VERSION "dbc-export 1 2025.20.8"

NS_ :

BS_:

BU_: BMS CP DAS DIF GTW HVP ICR PCS SCCM VCFRONT VCLEFT VCRIGHT VCSEC

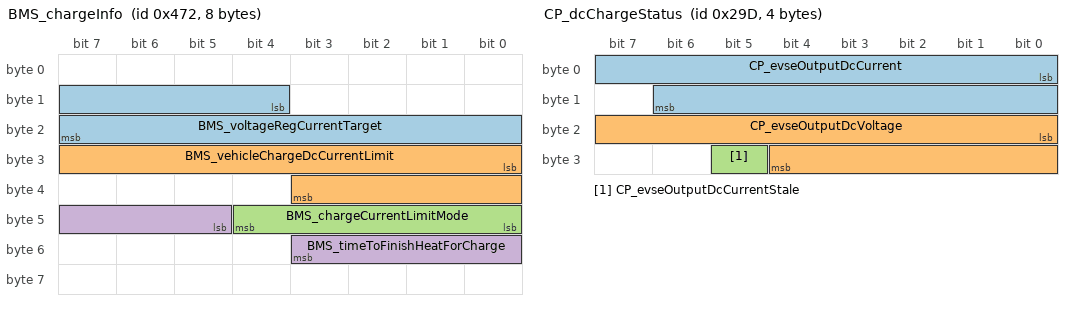
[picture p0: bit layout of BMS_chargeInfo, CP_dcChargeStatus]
BO_ 1138 BMS_chargeInfo: 8 BMS
 SG_ BMS_voltageRegCurrentTarget : 12|12@1+ (0.5,0) [0|2047.5] "A" Vector__XXX
 SG_ BMS_vehicleChargeDcCurrentLimit : 24|12@1+ (0.5,0) [0|2047.5] "A" Vector__XXX
 SG_ BMS_chargeCurrentLimitMode : 40|5@1+ (1,0) [0|31] "" Vector__XXX
 SG_ BMS_timeToFinishHeatForCharge : 45|7@1+ (5,0) [0|600] "min" Vector__XXX

BO_ 658 BMS_socStatus: 8 BMS
 SG_ BMS_userChargeCurrentLimitMode : 58|3@1+ (1,0) [0|7] "" Vector__XXX

BO_ 669 CP_dcChargeStatus: 4 CP
 SG_ CP_evseOutputDcCurrent : 0|15@1- (0.125,0) [-2048|2047.875] "A" Vector__XXX
 SG_ CP_evseOutputDcVoltage : 16|13@1+ (0.07324219,0) [0|599.92675822] "V" Vector__XXX
 SG_ CP_evseOutputDcCurrentStale : 29|1@1+ (1,0) [0|1] "" Vector__XXX

BO_ 541 CP_evseStatus: 8 CP
 SG_ CP_evseAccept : 0|1@1+ (1,0) [0|1] "" Vector__XXX
 SG_ CP_evseRequest : 1|1@1+ (1,0) [0|1] "" Vector__XXX
 SG_ CP_proximity : 2|2@1+ (1,0) [1|3] "" Vector__XXX
 SG_ CP_pilot : 4|3@1+ (1,0) [0|6] "" Vector__XXX
 SG_ CP_digitalCommsEstablished : 7|1@1+ (1,0) [0|1] "" Vector__XXX
 SG_ CP_pilotCurrent : 8|8@1+ (0.5,0) [0|127.5] "A" Vector__XXX
 SG_ CP_cableType : 16|3@1+ (1,0) [0|7] "" Vector__XXX
 SG_ CP_iecPilotState : 19|4@1+ (1,0) [0|15] "" Vector__XXX
 SG_ CP_plcSupported : 23|1@1+ (1,0) [0|1] "" Vector__XXX
 SG_ CP_cableCurrentLimit : 24|7@1+ (1,0) [0|127] "A" Vector__XXX
 SG_ CP_teslaSwcanState : 34|4@1+ (1,0) [0|15] "" Vector__XXX
 SG_ CP_evseChargeType_UI : 38|2@1+ (1,0) [0|3] "" Vector__XXX
 SG_ CP_gbState : 40|4@1+ (1,0) [0|15] "" Vector__XXX
 SG_ CP_gbdcStopChargeReason : 44|4@1+ (1,0) [0|15] "" Vector__XXX
 SG_ CP_gbdcFailureReason : 48|2@1+ (1,0) [0|3] "" Vector__XXX
 SG_ CP_gbdcChargeAttempts : 50|2@1+ (1,0) [0|3] "" Vector__XXX
 SG_ CP_acChargeState : 52|3@1+ (1,0) [0|7] "" Vector__XXX
 SG_ CP_teslaDcState : 56|4@1+ (1,0) [0|15] "" Vector__XXX

BO_ 1001 DAS_bodyControls: 8 DAS
 SG_ DAS_headlightRequest : 0|2@1+ (1,0) [0|3] "" Vector__XXX
 SG_ DAS_hazardLightRequest : 2|2@1+ (1,0) [0|2] "" Vector__XXX
 SG_ DAS_wiperSpeed : 4|4@1+ (1,0) [0|15] "" Vector__XXX
 SG_ DAS_turnIndicatorRequest : 8|3@1+ (1,0) [0|7] "" Vector__XXX
 SG_ DAS_highLowBeamDecision : 11|2@1+ (1,0) [0|2] "" Vector__XXX
 SG_ DAS_heaterRequest : 13|2@1+ (1,0) [1|3] "" Vector__XXX
 SG_ DAS_highLowBeamOffReason : 15|3@1+ (1,0) [0|7] "" Vector__XXX
 SG_ DAS_forwardCamHeaterDutyCycle : 18|4@1+ (0.06666667,0) [0|1] "-" Vector__XXX
 SG_ DAS_dynamicBrakeLightRequest : 22|1@1+ (1,0) [0|1] "" Vector__XXX
 SG_ DAS_radarHeaterRequest : 23|1@1+ (1,0) [0|1] "" Vector__XXX
 SG_ DAS_ahlbOverride : 24|1@1+ (1,0) [0|1] "" Vector__XXX
 SG_ DAS_mirrorFoldRequest : 25|2@1+ (1,0) [0|2] "" Vector__XXX
 SG_ DAS_wiperWashRequest : 27|1@1+ (1,0) [0|1] "" Vector__XXX
 SG_ DAS_ulcConfirmationRequestActive : 28|1@1+ (1,0) [0|1] "" Vector__XXX
 SG_ DAS_overrideWiperSetting : 29|1@1+ (1,0) [0|1] "" Vector__XXX
 SG_ DAS_autoWiperState : 30|3@1+ (1,0) [0|7] "" Vector__XXX
 SG_ DAS_turnIndicatorRequestReason : 33|5@1+ (1,0) [0|31] "" Vector__XXX
 SG_ DAS_forwardRadarPowerRequest : 38|1@1+ (1,0) [0|1] "" Vector__XXX
 SG_ DAS_driverDomeLightRequest : 39|1@1+ (1,0) [0|1] "" Vector__XXX
 SG_ DAS_drivePowerStateRequest : 43|1@1+ (1,0) [0|1] "" Vector__XXX
 SG_ DAS_enableIcrDataCollection : 44|1@1+ (1,0) [0|1] "" Vector__XXX
 SG_ DAS_rPillarCamHeaterDutyCycle : 45|4@1+ (0.06666667,0) [0|1] "-" Vector__XXX
 SG_ DAS_adaptiveHighBeamIsFaulted : 49|1@1+ (1,0) [0|1] "" Vector__XXX
 SG_ DAS_restrictDoorReleaseLeft : 50|1@1+ (1,0) [0|1] "" Vector__XXX
 SG_ DAS_restrictDoorReleaseRight : 51|1@1+ (1,0) [0|1] "" Vector__XXX
 SG_ DAS_bodyControlsCounter : 52|4@1+ (1,0) [0|15] "" Vector__XXX
 SG_ DAS_bodyControlsChecksum : 56|8@1+ (1,0) [0|255] "" Vector__XXX

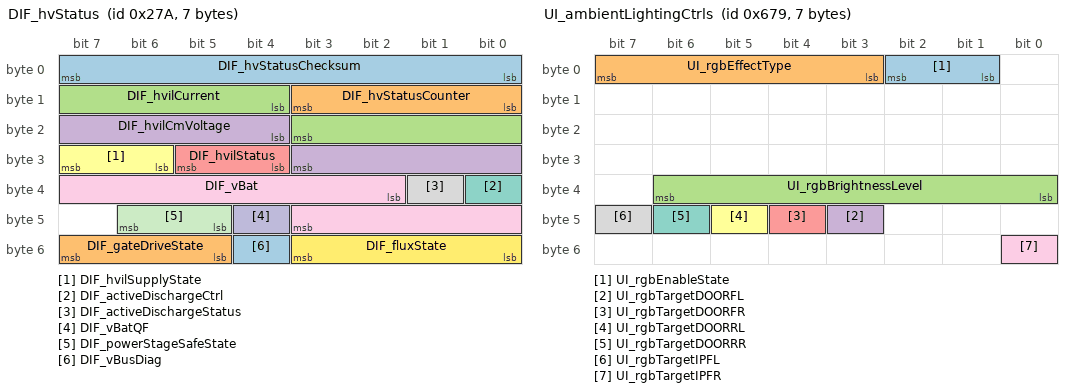
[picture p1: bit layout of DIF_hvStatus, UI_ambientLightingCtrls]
BO_ 634 DIF_hvStatus: 7 DIF
 SG_ DIF_hvStatusChecksum : 0|8@1+ (1,0) [0|255] "" Vector__XXX
 SG_ DIF_hvStatusCounter : 8|4@1+ (1,0) [0|15] "" Vector__XXX
 SG_ DIF_hvilCurrent : 12|8@1+ (0.1,0) [0|25.5] "mA" Vector__XXX
 SG_ DIF_hvilCmVoltage : 20|8@1+ (0.08,0) [0|20.4] "V" Vector__XXX
 SG_ DIF_hvilStatus : 28|2@1+ (1,0) [0|2] "" Vector__XXX
 SG_ DIF_hvilSupplyState : 30|2@1+ (1,0) [0|3] "" Vector__XXX
 SG_ DIF_activeDischargeCtrl : 32|1@1+ (1,0) [0|1] "" Vector__XXX
 SG_ DIF_activeDischargeStatus : 33|1@1+ (1,0) [0|1] "" Vector__XXX
 SG_ DIF_vBat : 34|10@1+ (1,0) [0|1023] "V" Vector__XXX
 SG_ DIF_vBatQF : 44|1@1+ (1,0) [0|1] "" Vector__XXX
 SG_ DIF_powerStageSafeState : 45|2@1+ (1,0) [0|3] "" Vector__XXX
 SG_ DIF_fluxState : 48|4@1+ (1,0) [0|15] "" Vector__XXX
 SG_ DIF_vBusDiag : 52|1@1+ (1,0) [0|1] "" Vector__XXX
 SG_ DIF_gateDriveState : 53|3@1+ (1,0) [0|7] "" Vector__XXX

BO_ 784 HVP_info: 8 HVP
 SG_ HVP_infoIndex M : 0|8@1+ (1,0) [0|255] "" Vector__XXX
 SG_ HVP_buildType m10 : 8|3@1+ (1,0) [0|7] "" Vector__XXX
 SG_ HVP_buildConfigId m10 : 16|16@1+ (1,0) [0|65535] "" Vector__XXX
 SG_ HVP_hardwareId m10 : 32|16@1+ (1,0) [0|65535] "" Vector__XXX
 SG_ HVP_componentId m10 : 48|16@1+ (1,0) [0|65535] "" Vector__XXX
 SG_ HVP_pcbaId m11 : 16|8@1+ (1,0) [0|255] "" Vector__XXX
 SG_ HVP_assemblyId m11 : 24|8@1+ (1,0) [0|255] "" Vector__XXX
 SG_ HVP_usageId m11 : 32|16@1+ (1,0) [0|65535] "" Vector__XXX
 SG_ HVP_subUsageId m11 : 48|16@1+ (1,0) [0|65535] "" Vector__XXX
 SG_ HVP_platformType m13 : 8|8@1+ (1,0) [0|255] "" Vector__XXX
 SG_ HVP_appCrc m13 : 32|32@1+ (1,0) [0|4294967295] "" Vector__XXX
 SG_ HVP_appGitHash m17 : 8|56@1+ (1,0) [0|7.20575940379e+16] "" Vector__XXX
 SG_ HVP_bootGitHash m18 : 8|56@1+ (1,0) [0|7.20575940379e+16] "" Vector__XXX
 SG_ HVP_bootUdsProtoVersion m20 : 8|8@1+ (1,0) [0|255] "" Vector__XXX
 SG_ HVP_bootCrc m20 : 32|32@1+ (1,0) [0|4294967295] "" Vector__XXX

BO_ 941 ICR_info: 8 ICR
 SG_ ICR_infoIndex M : 0|8@1+ (1,0) [0|255] "" Vector__XXX
 SG_ ICR_infoBuildType m10 : 8|3@1+ (1,0) [0|7] "" Vector__XXX
 SG_ ICR_infoPcbaId m11 : 32|8@1+ (1,0) [0|255] "" Vector__XXX
 SG_ ICR_infoAssemblyId m11 : 40|8@1+ (1,0) [0|255] "" Vector__XXX
 SG_ ICR_infoUsageId m11 : 48|16@1+ (1,0) [0|65535] "" Vector__XXX
 SG_ ICR_infoAppCrc m13 : 8|32@1+ (1,0) [0|4294967295] "" Vector__XXX
 SG_ ICR_infoBoardPartNumber17 m25 : 8|56@1+ (1,0) [0|7.20575940379e+16] "" Vector__XXX
 SG_ ICR_infoBoardPartNumber814 m26 : 8|56@1+ (1,0) [0|7.20575940379e+16] "" Vector__XXX
 SG_ ICR_infoBoardPartNumber1520 m27 : 8|48@1+ (1,0) [0|281474976710655] "" Vector__XXX

BO_ 964 PCS_info: 8 PCS
 SG_ PCS_infoIndex M : 0|8@1+ (1,0) [0|255] "" Vector__XXX
 SG_ PCS_buildType m10 : 8|8@1+ (1,0) [0|255] "" Vector__XXX
 SG_ PCS_buildConfigId m10 : 16|16@1+ (1,0) [0|65535] "" Vector__XXX
 SG_ PCS_hardwareId m10 : 32|16@1+ (1,0) [0|65535] "" Vector__XXX
 SG_ PCS_componentId m10 : 48|16@1+ (1,0) [0|65535] "" Vector__XXX
 SG_ PCS_pcbaId m11 : 16|8@1+ (1,0) [0|255] "" Vector__XXX
 SG_ PCS_assemblyId m11 : 24|8@1+ (1,0) [0|255] "" Vector__XXX
 SG_ PCS_usageId m11 : 32|16@1+ (1,0) [0|65535] "" Vector__XXX
 SG_ PCS_subUsageId m11 : 48|16@1+ (1,0) [0|65535] "" Vector__XXX
 SG_ PCS_platformType m13 : 8|8@1+ (1,0) [0|255] "" Vector__XXX
 SG_ PCS_appCrc m13 : 32|32@1+ (1,0) [0|4294967295] "" Vector__XXX
 SG_ PCS_cpu2AppCrc m16 : 32|32@1+ (1,0) [0|4294967295] "" Vector__XXX
 SG_ PCS_appGitHash m17 : 8|56@1+ (1,0) [0|7.20575940379e+16] "" Vector__XXX
 SG_ PCS_bootGitHash m18 : 8|56@1+ (1,0) [0|7.20575940379e+16] "" Vector__XXX
 SG_ PCS_bootUdsProtoVersion m20 : 8|8@1+ (1,0) [0|255] "" Vector__XXX
 SG_ PCS_bootCrc m20 : 32|32@1+ (1,0) [0|4294967295] "" Vector__XXX

BO_ 816 SCCM_info: 8 SCCM
 SG_ SCCM_infoIndex M : 0|8@1+ (1,0) [0|255] "" Vector__XXX
 SG_ SCCM_infoBuildType m10 : 8|8@1+ (1,0) [0|255] "" Vector__XXX
 SG_ SCCM_infoBuildConfigId m10 : 16|16@1+ (1,0) [0|65535] "" Vector__XXX
 SG_ SCCM_infoHardwareId m10 : 32|16@1+ (1,0) [0|65535] "" Vector__XXX
 SG_ SCCM_infoComponentId m10 : 48|16@1+ (1,0) [0|65535] "" Vector__XXX
 SG_ SCCM_infoPcbaId m11 : 16|8@1+ (1,0) [0|255] "" Vector__XXX
 SG_ SCCM_infoAssemblyId m11 : 24|8@1+ (1,0) [0|255] "" Vector__XXX
 SG_ SCCM_infoUsageId m11 : 32|16@1+ (1,0) [0|65535] "" Vector__XXX
 SG_ SCCM_infoSubUsageId m11 : 48|16@1+ (1,0) [0|65535] "" Vector__XXX
 SG_ SCCM_infoPlatformType m13 : 8|8@1+ (1,0) [0|255] "" Vector__XXX
 SG_ SCCM_infoAppCrc m13 : 39|32@0+ (1,0) [0|4294967295] "" Vector__XXX
 SG_ SCCM_infoBootSvnRev m14 : 8|24@1+ (1,0) [0|16777215] "" Vector__XXX
 SG_ SCCM_infoBootSvnUrlHash m14 : 32|32@1+ (1,0) [0|4294967295] "" Vector__XXX
 SG_ SCCM_infoSubcomponent1Version m16 : 16|32@1+ (1,0) [0|4294967295] "" Vector__XXX
 SG_ SCCM_infoAppSvnHash m17 : 8|56@1+ (1,0) [0|7.20575940379e+16] "" Vector__XXX
 SG_ SCCM_infoBootSvnHash m18 : 8|56@1+ (1,0) [0|7.20575940379e+16] "" Vector__XXX
 SG_ SCCM_infoUdsProtoVersion m20 : 8|8@1+ (1,0) [0|255] "" Vector__XXX
 SG_ SCCM_infoBootCrc m20 : 32|32@1+ (1,0) [0|4294967295] "" Vector__XXX

BO_ 1657 UI_ambientLightingCtrls: 7 GTW
 SG_ UI_rgbEnableState : 1|2@1+ (1,0) [0|3] "" Vector__XXX
 SG_ UI_rgbEffectType : 3|5@1+ (1,0) [0|31] "" Vector__XXX
 SG_ UI_rgbBrightnessLevel : 32|7@1+ (1,0) [0|100] "%" Vector__XXX
 SG_ UI_rgbTargetDOORFL : 43|1@1+ (1,0) [0|1] "" Vector__XXX
 SG_ UI_rgbTargetDOORFR : 44|1@1+ (1,0) [0|1] "" Vector__XXX
 SG_ UI_rgbTargetDOORRL : 45|1@1+ (1,0) [0|1] "" Vector__XXX
 SG_ UI_rgbTargetDOORRR : 46|1@1+ (1,0) [0|1] "" Vector__XXX
 SG_ UI_rgbTargetIPFL : 47|1@1+ (1,0) [0|1] "" Vector__XXX
 SG_ UI_rgbTargetIPFR : 48|1@1+ (1,0) [0|1] "" Vector__XXX

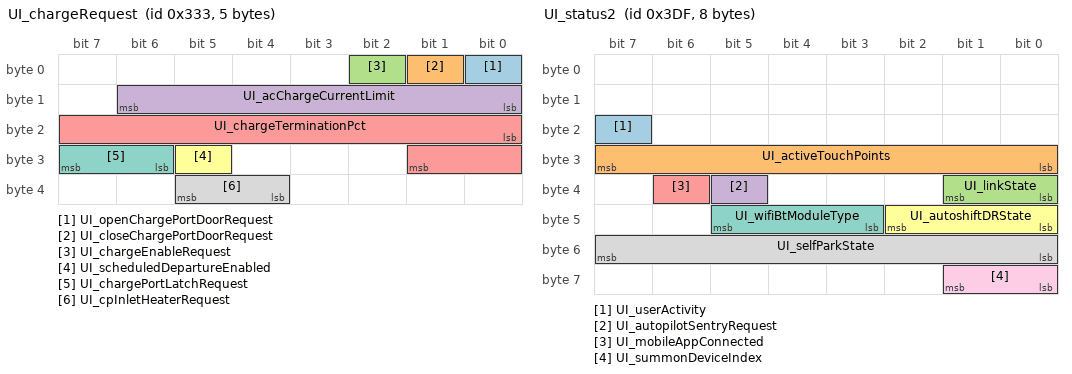
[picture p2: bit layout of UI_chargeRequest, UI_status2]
BO_ 819 UI_chargeRequest: 5 GTW
 SG_ UI_openChargePortDoorRequest : 0|1@1+ (1,0) [0|1] "" Vector__XXX
 SG_ UI_closeChargePortDoorRequest : 1|1@1+ (1,0) [0|1] "" Vector__XXX
 SG_ UI_chargeEnableRequest : 2|1@1+ (1,0) [0|1] "" Vector__XXX
 SG_ UI_acChargeCurrentLimit : 8|7@1+ (1,0) [0|126] "A" Vector__XXX
 SG_ UI_chargeTerminationPct : 16|10@1+ (0.1,0) [5|100] "%" Vector__XXX
 SG_ UI_scheduledDepartureEnabled : 29|1@1+ (1,0) [0|1] "" Vector__XXX
 SG_ UI_chargePortLatchRequest : 30|2@1+ (1,0) [0|3] "" Vector__XXX
 SG_ UI_cpInletHeaterRequest : 36|2@1+ (1,0) [0|3] "" Vector__XXX

BO_ 991 UI_status2: 8 GTW
 SG_ UI_userActivity : 23|1@1+ (1,0) [0|1] "" Vector__XXX
 SG_ UI_activeTouchPoints : 24|8@1+ (1,0) [0|255] "1" Vector__XXX
 SG_ UI_linkState : 32|2@1+ (1,0) [0|3] "" Vector__XXX
 SG_ UI_autopilotSentryRequest : 37|1@1+ (1,0) [0|1] "" Vector__XXX
 SG_ UI_mobileAppConnected : 38|1@1+ (1,0) [0|1] "" Vector__XXX
 SG_ UI_autoshiftDRState : 40|3@1+ (1,0) [0|7] "" Vector__XXX
 SG_ UI_wifiBtModuleType : 43|3@1+ (1,0) [0|7] "" Vector__XXX
 SG_ UI_selfParkState : 48|8@1+ (1,0) [0|254] "" Vector__XXX
 SG_ UI_summonDeviceIndex : 56|2@1+ (1,0) [0|3] "" Vector__XXX

BO_ 663 UI_suspensionControl: 8 GTW
 SG_ UI_adaptiveRideRequest : 3|2@1+ (1,0) [0|3] "" Vector__XXX
 SG_ UI_geofenceLevelingRequest : 7|3@1+ (1,0) [0|7] "" Vector__XXX

BO_ 947 UI_vehicleControl2: 8 GTW
 SG_ UI_gloveboxRequest : 0|1@1+ (1,0) [0|1] "" Vector__XXX
 SG_ UI_trunkRequest : 1|1@1+ (1,0) [0|1] "" Vector__XXX
 SG_ UI_PINToDriveEnabled : 6|1@1+ (1,0) [0|1] "" Vector__XXX
 SG_ UI_PINToDrivePassed : 7|1@1+ (1,0) [0|1] "" Vector__XXX
 SG_ UI_disableMirrorAutoDim : 8|1@1+ (1,0) [0|1] "" Vector__XXX
 SG_ UI_lightSwitch : 9|3@1+ (1,0) [0|7] "" Vector__XXX
 SG_ UI_readyToAddKey : 12|1@1+ (1,0) [0|1] "" Vector__XXX
 SG_ UI_alarmTriggerRequest : 13|1@1+ (1,0) [0|1] "" Vector__XXX
 SG_ UI_displayOnForUser : 18|1@1+ (1,0) [0|1] "" Vector__XXX
 SG_ UI_BLEPushNotificationRequest : 20|1@1+ (1,0) [0|1] "" Vector__XXX
 SG_ UI_keepAutopilotAwake : 22|1@1+ (1,0) [0|1] "" Vector__XXX
 SG_ UI_batteryPreconditioningRequest : 23|1@1+ (1,0) [0|1] "" Vector__XXX
 SG_ UI_autopilotPowerStateRequest : 25|2@1+ (1,0) [0|3] "" Vector__XXX
 SG_ UI_autoRollWindowsOnLockEnable : 29|1@1+ (1,0) [0|1] "" Vector__XXX
 SG_ UI_steeringWheelHeatReq : 33|1@1+ (1,0) [0|1] "" Vector__XXX
 SG_ UI_disableHorn : 34|1@1+ (1,0) [0|1] "" Vector__XXX
 SG_ UI_frontLeftSeatFanReq : 37|2@1+ (1,0) [0|3] "" Vector__XXX
 SG_ UI_frontRightSeatAutoClimateReq : 39|1@1+ (1,0) [0|1] "" Vector__XXX
 SG_ UI_frontRightSeatFanReq : 40|2@1+ (1,0) [0|3] "" Vector__XXX
 SG_ UI_frontLeftSeatAutoClimateReq : 56|1@1+ (1,0) [0|1] "" Vector__XXX
 SG_ UI_wiperHeaterReq : 57|1@1+ (1,0) [0|1] "" Vector__XXX
 SG_ UI_silentAlarm : 61|1@1+ (1,0) [0|1] "" Vector__XXX

BO_ 609 VCFRONT_12VBatteryStatus: 8 VCFRONT
 SG_ VCFRONT_12VBatteryStatusIndex M : 0|3@1+ (1,0) [0|7] "" Vector__XXX
 SG_ VCFRONT_good12VforUpdate : 46|1@1+ (1,0) [0|1] "" Vector__XXX
 SG_ VCFRONT_LVLoadRequest : 47|1@1+ (1,0) [0|1] "" Vector__XXX
 SG_ VCFRONT_12VBatteryStatusCounter : 52|4@1+ (1,0) [0|15] "" Vector__XXX
 SG_ VCFRONT_12VBatteryStatusChecksum : 56|8@1+ (1,0) [0|255] "" Vector__XXX
 SG_ VCFRONT_batterySupportRequest m1 : 3|1@1+ (1,0) [0|1] "" Vector__XXX
 SG_ VCFRONT_batterySMState m1 : 4|4@1+ (1,0) [0|15] "" Vector__XXX
 SG_ VCFRONT_eFuseRecoveryStateDBG m1 : 8|3@1+ (1,0) [0|7] "" Vector__XXX
 SG_ VCFRONT_batteryLINScheduleDBG m1 : 11|3@1+ (1,0) [0|6] "" Vector__XXX
 SG_ VCFRONT_resistanceEstimationTest m1 : 14|2@1+ (1,0) [0|3] "" Vector__XXX
 SG_ VCFRONT_IBSCurrent m1 : 16|16@1- (0.005,0) [-163.84|163.835] "A" Vector__XXX
 SG_ VCFRONT_IBSVoltage m1 : 32|14@1+ (0.005443676,0) [0|65.535] "V" Vector__XXX
 SG_ VCFRONT_reverseBatteryFault m1 : 48|1@1+ (1,0) [0|1] "" Vector__XXX
 SG_ VCFRONT_LVBatterySupported m1 : 49|1@1+ (1,0) [0|1] "" Vector__XXX
 SG_ VCFRONT_LVBatteryCannotSupportVe m1 : 50|1@1+ (1,0) [0|1] "" Vector__XXX
 SG_ VCFRONT_goodTemp12VforUpdate m1 : 51|1@1+ (1,0) [0|1] "" Vector__XXX
 SG_ VCFRONT_12VBatteryTargetVoltage m2 : 3|13@1+ (0.01,0) [0|65.535] "V" Vector__XXX
 SG_ VCFRONT_IBSTemperature m2 : 16|11@1+ (0.1,-24) [-24|124] "degC" Vector__XXX
 SG_ VCFRONT_currentSensorMismatchLea m2 : 27|7@1+ (2,0) [0|254] "PCT" Vector__XXX
 SG_ VCFRONT_LVBatteryEnergyRemaining m2 : 37|7@1+ (1,0) [0|127] "%" Vector__XXX
 SG_ VCFRONT_LVBatteryStatusForDrive m2 : 44|2@1+ (1,0) [0|3] "" Vector__XXX
 SG_ VCFRONT_LVBatteryType m2 : 48|3@1+ (1,0) [0|7] "" Vector__XXX
 SG_ VCFRONT_resistanceEstimationNeed m2 : 51|1@1+ (1,0) [0|1] "" Vector__XXX
 SG_ VCFRONT_IBSVoltageFiltered m3 : 3|14@1+ (0.005443676,0) [0|65.535] "V" Vector__XXX
 SG_ VCFRONT_LVBMS_LVBusVoltageSource m3 : 17|2@1+ (1,0) [0|3] "" Vector__XXX
 SG_ VCFRONT_LVBMS_LVPackCurrentSourc m3 : 19|2@1+ (1,0) [0|3] "" Vector__XXX
 SG_ VCFRONT_LVBatterySupportRqrdTrig m3 : 24|14@1+ (1,0) [0|16383] "" Vector__XXX
 SG_ VCFRONT_goodForPCSPowerCycleLeak m3 : 40|5@1+ (0.0005,0) [0|0.0155] "Ah" Vector__XXX
 SG_ VCFRONT_LVBusControlsFutile m3 : 45|1@1+ (1,0) [0|1] "" Vector__XXX
 SG_ VCFRONT_resistanceEstimatio_0001 m3 : 48|1@1+ (1,0) [0|1] "" Vector__XXX
 SG_ VCFRONT_resistanceEstimatio_0002 m3 : 49|1@1+ (1,0) [0|1] "" Vector__XXX
 SG_ VCFRONT_goodLVChargeForUpdate m3 : 50|1@1+ (1,0) [0|1] "" Vector__XXX
 SG_ VCFRONT_opportunisticDCRTestNeed m3 : 51|1@1+ (1,0) [0|1] "" Vector__XXX
 SG_ VCFRONT_voltageProfile m4 : 3|2@1+ (1,0) [0|3] "" Vector__XXX
 SG_ VCFRONT_IBSAmpHours m4 : 5|14@1- (0.005,0) [-40.96|40.955] "Ah" Vector__XXX
 SG_ VCFRONT_IBSVoltageRawDBG m4 : 19|14@1+ (0.005443676,0) [0|65.535] "V" Vector__XXX
 SG_ VCFRONT_LVBatteryLINCommsDetecte m4 : 33|1@1+ (1,0) [0|1] "" Vector__XXX
 SG_ VCFRONT_voltageSensorMismatchLea m4 : 34|7@1+ (2,0) [0|254] "PCT" Vector__XXX
 SG_ VCFRONT_LVBatteryFctryLimOverrid m4 : 50|1@1+ (1,0) [0|1] "" Vector__XXX
 SG_ VCFRONT_LVBatterySPICommsDetecte m4 : 51|1@1+ (1,0) [0|1] "" Vector__XXX
 SG_ VCFRONT_targetCurrent m5 : 3|11@1+ (0.125,-127) [0|120] "A" Vector__XXX
 SG_ VCFRONT_PCSMia m5 : 14|1@1+ (1,0) [0|1] "" Vector__XXX
 SG_ VCFRONT_chargeNeeded m5 : 15|1@1+ (1,0) [0|1] "" Vector__XXX
 SG_ VCFRONT_voltageControlLoopIntegr m5 : 16|14@1+ (0.006,0) [0|65.535] "V" Vector__XXX
 SG_ VCFRONT_currentControlLoopIntegr m5 : 30|14@1+ (0.006,0) [0|65.535] "V" Vector__XXX

BO_ 1801 VCFRONT_logging0point1Hz: 8 VCFRONT
 SG_ VCFRONT_logging0point1HzIndex M : 0|5@1+ (1,0) [0|31] "" Vector__XXX
 SG_ VC_hcmlFactoryOfOrigin m26 : 5|2@1+ (1,0) [0|3] "" Vector__XXX
 SG_ VC_hcmlHellaPartNumberStatus m26 : 7|1@1+ (1,0) [0|1] "" Vector__XXX
 SG_ VC_hcmlHellaPartNumber m26 : 8|32@1+ (1,0) [0|4294967295] "-" Vector__XXX
 SG_ VC_hcmlCurrentBinMappingType m26 : 40|2@1+ (1,0) [0|3] "" Vector__XXX
 SG_ VC_hcmlCurrentBin0Value m26 : 42|3@1+ (1,0) [1|7] "" Vector__XXX
 SG_ VC_hcmlCurrentBin1Value m26 : 45|3@1+ (1,0) [1|7] "" Vector__XXX
 SG_ VC_hcmlCurrentBin2Value m26 : 48|3@1+ (1,0) [1|7] "" Vector__XXX
 SG_ VC_hcmlCurrentBin3Value m26 : 51|3@1+ (1,0) [1|7] "" Vector__XXX
 SG_ VC_hcmlCurrentBin4Value m26 : 54|3@1+ (1,0) [1|7] "" Vector__XXX
 SG_ VC_hcmlCurrentBin5Value m26 : 57|3@1+ (1,0) [1|7] "" Vector__XXX
 SG_ VC_hcmlRegionAndSide m26 : 60|3@1+ (1,0) [1|7] "" Vector__XXX
 SG_ VC_hcmrFactoryOfOrigin m27 : 5|2@1+ (1,0) [0|3] "" Vector__XXX
 SG_ VC_hcmrHellaPartNumberStatus m27 : 7|1@1+ (1,0) [0|1] "" Vector__XXX
 SG_ VC_hcmrHellaPartNumber m27 : 8|32@1+ (1,0) [0|4294967295] "-" Vector__XXX
 SG_ VC_hcmrCurrentBinMappingType m27 : 40|2@1+ (1,0) [0|3] "" Vector__XXX
 SG_ VC_hcmrCurrentBin0Value m27 : 42|3@1+ (1,0) [1|7] "" Vector__XXX
 SG_ VC_hcmrCurrentBin1Value m27 : 45|3@1+ (1,0) [1|7] "" Vector__XXX
 SG_ VC_hcmrCurrentBin2Value m27 : 48|3@1+ (1,0) [1|7] "" Vector__XXX
 SG_ VC_hcmrCurrentBin3Value m27 : 51|3@1+ (1,0) [1|7] "" Vector__XXX
 SG_ VC_hcmrCurrentBin4Value m27 : 54|3@1+ (1,0) [1|7] "" Vector__XXX
 SG_ VC_hcmrCurrentBin5Value m27 : 57|3@1+ (1,0) [1|7] "" Vector__XXX
 SG_ VC_hcmrRegionAndSide m27 : 60|3@1+ (1,0) [1|7] "" Vector__XXX

BO_ 897 VCFRONT_logging1Hz: 8 VCFRONT
 SG_ VCFRONT_logging1HzIndex M : 0|5@1+ (1,0) [0|31] "" Vector__XXX
 SG_ VCFRONT_batteryDischArbState m21 : 56|3@1+ (1,0) [0|7] "" Vector__XXX

BO_ 957 VCFRONT_parkedEnergyLoss: 8 VCFRONT
 SG_ VCFRONT_energyLossIndex M : 0|3@1+ (1,0) [0|7] "" Vector__XXX
 SG_ VCFRONT_userEnergyLossSinceDrive m1 : 8|14@1+ (0.01,0) [0|163.83] "kWh" Vector__XXX
 SG_ VCFRONT_preconditioningEner_0001 m1 : 22|14@1+ (0.01,0) [0|163.83] "kWh" Vector__XXX
 SG_ VCFRONT_cabinOverheatEnergy_0001 m1 : 36|14@1+ (0.01,0) [0|163.83] "kWh" Vector__XXX
 SG_ VCFRONT_mobileAppEnergyLoss_0001 m1 : 50|14@1+ (0.01,0) [0|163.83] "kWh" Vector__XXX
 SG_ VCFRONT_summonStandbyEnergy_0001 m2 : 8|14@1+ (0.01,0) [0|163.83] "kWh" Vector__XXX
 SG_ VCFRONT_sentryModeEnergyLos_0001 m2 : 22|14@1+ (0.01,0) [0|163.83] "kWh" Vector__XXX
 SG_ VCFRONT_backgroundEnergyLos_0001 m2 : 36|14@1+ (0.01,0) [0|163.83] "kWh" Vector__XXX
 SG_ VCFRONT_evapDryingEnergyLos_0001 m2 : 50|14@1+ (0.01,0) [0|163.83] "kWh" Vector__XXX
 SG_ VCFRONT_userEnergyLossSinceCharg m3 : 8|14@1+ (0.01,0) [0|163.83] "kWh" Vector__XXX
 SG_ VCFRONT_preconditioningEnergyLos m3 : 22|14@1+ (0.01,0) [0|163.83] "kWh" Vector__XXX
 SG_ VCFRONT_cabinOverheatEnergyLossS m3 : 36|14@1+ (0.01,0) [0|163.83] "kWh" Vector__XXX
 SG_ VCFRONT_mobileAppEnergyLossSince m3 : 50|14@1+ (0.01,0) [0|163.83] "kWh" Vector__XXX
 SG_ VCFRONT_summonStandbyEnergyLossS m4 : 8|14@1+ (0.01,0) [0|163.83] "kWh" Vector__XXX
 SG_ VCFRONT_sentryModeEnergyLossSinc m4 : 22|14@1+ (0.01,0) [0|163.83] "kWh" Vector__XXX
 SG_ VCFRONT_backgroundEnergyLossSinc m4 : 36|14@1+ (0.01,0) [0|163.83] "kWh" Vector__XXX
 SG_ VCFRONT_evapDryingEnergyLossSinc m4 : 50|14@1+ (0.01,0) [0|163.83] "kWh" Vector__XXX

BO_TX_BU_ 1138 : BMS;
BO_TX_BU_ 658 : BMS;
BO_TX_BU_ 669 : CP;
BO_TX_BU_ 541 : CP;
BO_TX_BU_ 1001 : DAS;
BO_TX_BU_ 634 : DIF;
BO_TX_BU_ 784 : HVP;
BO_TX_BU_ 941 : ICR;
BO_TX_BU_ 964 : PCS;
BO_TX_BU_ 816 : SCCM;
BO_TX_BU_ 1657 : GTW;
BO_TX_BU_ 819 : GTW;
BO_TX_BU_ 991 : GTW;
BO_TX_BU_ 663 : GTW;
BO_TX_BU_ 947 : GTW;
BO_TX_BU_ 609 : VCFRONT;
BO_TX_BU_ 1801 : VCFRONT;
BO_TX_BU_ 897 : VCFRONT;
BO_TX_BU_ 957 : VCFRONT;

CM_ "Tesla Model Y CAN bus database; bus VEH; firmware 2025.20.8. Decoded CAN signal definitions (layout, scaling, units, value tables).";
CM_ BU_ BMS "High-voltage battery management system";
CM_ BU_ CP "Charge port controller";
CM_ BU_ DAS "Driver assistance computer";
CM_ BU_ DIF "Front drive inverter";
CM_ BU_ GTW "Gateway";
CM_ BU_ HVP "High-voltage processor (pack contactor and isolation controller)";
CM_ BU_ ICR "ICR ECU";
CM_ BU_ PCS "Power conversion system (on-board charger and DC-DC converter)";
CM_ BU_ SCCM "Steering column control module";
CM_ BU_ VCFRONT "Front body controller";
CM_ BU_ VCLEFT "Left body controller";
CM_ BU_ VCRIGHT "Right body controller";
CM_ BU_ VCSEC "Vehicle security controller";
CM_ BO_ 1138 "High-voltage battery management system message: charge info";
CM_ SG_ 1138 BMS_voltageRegCurrentTarget "DC current target based on voltage regulator";
CM_ SG_ 1138 BMS_vehicleChargeDcCurrentLimit "Charge current target after all aggregating all vehicle-side limits, exclude EVSE limits";
CM_ SG_ 1138 BMS_chargeCurrentLimitMode "BMS charging current limiting factor";
CM_ SG_ 1138 BMS_timeToFinishHeatForCharge "High-voltage battery management system: time to finish heat for charge; raw 127 = signal not available (SNA)";
CM_ BO_ 658 "High-voltage battery management system message: soc status";
CM_ SG_ 658 BMS_userChargeCurrentLimitMode "BMS' user-facing reason for charge being either limited or not limited";
CM_ BO_ 669 "Charge port controller message: dc charge status";
CM_ SG_ 669 CP_evseOutputDcCurrent "The DC EVSE's measured output current";
CM_ SG_ 669 CP_evseOutputDcVoltage "The DC EVSE's measured output voltage";
CM_ SG_ 669 CP_evseOutputDcCurrentStale "Indicates whether the data in CP_evseOutputDcCurrent has not been updated with new info from the DC EVSE recently";
CM_ BO_ 541 "Charge port controller message: evse status";
CM_ SG_ 541 CP_evseAccept "State of pilot EVSE accept state";
CM_ SG_ 541 CP_evseRequest "Request to close AC EVSE relays, used when digital communications have been established";
CM_ SG_ 541 CP_proximity "Sensed state of proximity for all inlets; raw 0 = signal not available (SNA)";
CM_ SG_ 541 CP_pilot "State of EVSE pilot signal sensed by the charge port; raw 7 = signal not available (SNA)";
CM_ SG_ 541 CP_digitalCommsEstablished "Indicates whether digital communications have been established with an EVSE";
CM_ SG_ 541 CP_pilotCurrent "Line current limit detected from pilot signal";
CM_ SG_ 541 CP_cableType "Type of charge cable detected; raw 4 = signal not available (SNA)";
CM_ SG_ 541 CP_iecPilotState "State of the control pilot as defined in IEC-61851-1; raw 9 = signal not available (SNA)";
CM_ SG_ 541 CP_plcSupported "Indicates whether PLC hardware is populated for CCS charging support";
CM_ SG_ 541 CP_cableCurrentLimit "Charge port controller: cable current limit";
CM_ SG_ 541 CP_teslaSwcanState "Charge port controller: tesla swcan state";
CM_ SG_ 541 CP_evseChargeType_UI "Reports the type of Electric Vehicle Supply Equipment (EVSE) connected.";
CM_ SG_ 541 CP_gbState "State of GB DC charging";
CM_ SG_ 541 CP_gbdcStopChargeReason "Reason for stopping GB DC charging";
CM_ SG_ 541 CP_gbdcFailureReason "Reason for failure of GB DC charging";
CM_ SG_ 541 CP_gbdcChargeAttempts "Number of GB DC charging retries used";
CM_ SG_ 541 CP_acChargeState "Charge port controller: ac charge state";
CM_ SG_ 541 CP_teslaDcState "Reports the state of the Tesla direct current (DC) state machine.";
CM_ BO_ 1001 "Driver assistance computer message: body controls";
CM_ SG_ 1001 DAS_headlightRequest "The DAS request to the body controls ecu to turn on headlights.";
CM_ SG_ 1001 DAS_hazardLightRequest "The command from DAS to body controls to turn on the hazard lights.; raw 3 = signal not available (SNA)";
CM_ SG_ 1001 DAS_wiperSpeed "The auto wiper algorithm speed request to the body controller.";
CM_ SG_ 1001 DAS_turnIndicatorRequest "Reports Driver Assistance System (DAS) request to body controls to turn on/off the left or right turn indicator.";
CM_ SG_ 1001 DAS_highLowBeamDecision "The output of the automatic high beam algorithm, to turn the highbeams on or off.; raw 3 = signal not available (SNA)";
CM_ SG_ 1001 DAS_heaterRequest "The DAS request to the body controller to turn on the front glass heater in front of the triple camera.; raw 0 = signal not available (SNA)";
CM_ SG_ 1001 DAS_highLowBeamOffReason "The reason why automatic high beams are surpressed.; raw 5 = signal not available (SNA)";
CM_ SG_ 1001 DAS_forwardCamHeaterDutyCycle "Supplies the requested duty cycle of the front windshield camera heater";
CM_ SG_ 1001 DAS_dynamicBrakeLightRequest "Indicates if the dynamic brake light alogirthm is requesting pulsing brake lights.";
CM_ SG_ 1001 DAS_radarHeaterRequest "Reports the request from Driver Assistance System (DAS) to body controls to turn on heater to clear out fascia in front of the radar.";
CM_ SG_ 1001 DAS_ahlbOverride "Indicates if body controller should override UI switch and stalk state to allow auto high beam functionality";
CM_ SG_ 1001 DAS_mirrorFoldRequest "DAS request to fold or present mirrors.; raw 3 = signal not available (SNA)";
CM_ SG_ 1001 DAS_wiperWashRequest "Autowiper requests that the windshield be washed";
CM_ SG_ 1001 DAS_ulcConfirmationRequestActive "Driver assistance computer: ulc confirmation request active";
CM_ SG_ 1001 DAS_overrideWiperSetting "Autopilot wants to override the user's wiper setting to enable auto-wiper";
CM_ SG_ 1001 DAS_autoWiperState "DAS auto wiper internal state; raw 5 = signal not available (SNA)";
CM_ SG_ 1001 DAS_turnIndicatorRequestReason "Reports the reason that Driver Assistance System (DAS) is requesting a change to the turn indicator state from body controls.";
CM_ SG_ 1001 DAS_forwardRadarPowerRequest "Driver assistance computer: forward radar power request";
CM_ SG_ 1001 DAS_driverDomeLightRequest "DAS requests that driver side dome light be illuminated";
CM_ SG_ 1001 DAS_drivePowerStateRequest "Reports DAS request for vehicle power state Drive.";
CM_ SG_ 1001 DAS_enableIcrDataCollection "Driver assistance computer: enable icr data collection";
CM_ SG_ 1001 DAS_rPillarCamHeaterDutyCycle "Supplies the requested duty cycle of the right pillar camera heater";
CM_ SG_ 1001 DAS_adaptiveHighBeamIsFaulted "Indicates malfunctioning or unavailable input to the Adaptive High Beam system.";
CM_ SG_ 1001 DAS_restrictDoorReleaseLeft "Reports requests to inhibit left doors from being released.";
CM_ SG_ 1001 DAS_restrictDoorReleaseRight "Reports requests to inhibit right doors from being released.";
CM_ SG_ 1001 DAS_bodyControlsCounter "Driver assistance computer: body controls counter";
CM_ SG_ 1001 DAS_bodyControlsChecksum "Driver assistance computer: body controls checksum";
CM_ BO_ 634 "Front drive inverter message: hv status";
CM_ SG_ 634 DIF_hvStatusChecksum "Front drive inverter: hv status checksum";
CM_ SG_ 634 DIF_hvStatusCounter "Front drive inverter: hv status counter";
CM_ SG_ 634 DIF_hvilCurrent "HVIL Current";
CM_ SG_ 634 DIF_hvilCmVoltage "HVIL Common Mode Voltage";
CM_ SG_ 634 DIF_hvilStatus "Aggregated hardware and measured HVIL unit status; raw 3 = signal not available (SNA)";
CM_ SG_ 634 DIF_hvilSupplyState "Front drive inverter: hvil supply state";
CM_ SG_ 634 DIF_activeDischargeCtrl "Front drive inverter: active discharge ctrl";
CM_ SG_ 634 DIF_activeDischargeStatus "Active discharge status from HVIL_FAULT signal.";
CM_ SG_ 634 DIF_vBat "Reports the battery voltage measured by the Drive Inverter's local Analog to Digital Converter (ADC).";
CM_ SG_ 634 DIF_vBatQF "Front drive inverter: v bat QF";
CM_ SG_ 634 DIF_powerStageSafeState "Front drive inverter: power stage safe state";
CM_ SG_ 634 DIF_fluxState "Front drive inverter: flux state";
CM_ SG_ 634 DIF_vBusDiag "Front drive inverter: v bus diag";
CM_ SG_ 634 DIF_gateDriveState "Front drive inverter: gate drive state";
CM_ BO_ 784 "High-voltage processor (pack contactor and isolation controller) message: info";
CM_ SG_ 784 HVP_infoIndex "High-voltage processor (pack contactor and isolation controller): info index";
CM_ SG_ 784 HVP_buildType "High-voltage processor (pack contactor and isolation controller): build type";
CM_ SG_ 784 HVP_buildConfigId "High-voltage processor (pack contactor and isolation controller): build config id";
CM_ SG_ 784 HVP_hardwareId "High-voltage processor (pack contactor and isolation controller): hardware id";
CM_ SG_ 784 HVP_componentId "High-voltage processor (pack contactor and isolation controller): component id";
CM_ SG_ 784 HVP_pcbaId "High-voltage processor (pack contactor and isolation controller): pcba id";
CM_ SG_ 784 HVP_assemblyId "HVP's assigned assembly ID";
CM_ SG_ 784 HVP_usageId "HVP's assigned usage ID";
CM_ SG_ 784 HVP_subUsageId "HVP's assigned subusage ID";
CM_ SG_ 784 HVP_platformType "High-voltage processor (pack contactor and isolation controller): platform type";
CM_ SG_ 784 HVP_appCrc "High-voltage processor (pack contactor and isolation controller): app crc";
CM_ SG_ 784 HVP_appGitHash "High-voltage processor (pack contactor and isolation controller): app git hash";
CM_ SG_ 784 HVP_bootGitHash "High-voltage processor (pack contactor and isolation controller): boot git hash";
CM_ SG_ 784 HVP_bootUdsProtoVersion "High-voltage processor (pack contactor and isolation controller): boot uds proto version";
CM_ SG_ 784 HVP_bootCrc "High-voltage processor (pack contactor and isolation controller): boot crc";
CM_ BO_ 941 "ICR ECU message: info";
CM_ SG_ 941 ICR_infoIndex "ICR ECU: info index";
CM_ SG_ 941 ICR_infoBuildType "ICR ECU: info build type";
CM_ SG_ 941 ICR_infoPcbaId "ICR ECU: info pcba id";
CM_ SG_ 941 ICR_infoAssemblyId "ICR ECU: info assembly id";
CM_ SG_ 941 ICR_infoUsageId "ICR ECU: info usage id";
CM_ SG_ 941 ICR_infoAppCrc "ICR ECU: info app crc";
CM_ SG_ 941 ICR_infoBoardPartNumber17 "ICR ECU: info board part number17";
CM_ SG_ 941 ICR_infoBoardPartNumber814 "ICR ECU: info board part number814";
CM_ SG_ 941 ICR_infoBoardPartNumber1520 "ICR ECU: info board part number1520";
CM_ BO_ 964 "Power conversion system (on-board charger and DC-DC converter) message: info";
CM_ SG_ 964 PCS_infoIndex "Power conversion system (on-board charger and DC-DC converter): info index";
CM_ SG_ 964 PCS_buildType "Power conversion system (on-board charger and DC-DC converter): build type";
CM_ SG_ 964 PCS_buildConfigId "Power conversion system (on-board charger and DC-DC converter): build config id";
CM_ SG_ 964 PCS_hardwareId "Power conversion system (on-board charger and DC-DC converter): hardware id";
CM_ SG_ 964 PCS_componentId "Power conversion system (on-board charger and DC-DC converter): component id";
CM_ SG_ 964 PCS_pcbaId "PCBA ID portion of component hardware ID as reported by application";
CM_ SG_ 964 PCS_assemblyId "Power conversion system (on-board charger and DC-DC converter): assembly id";
CM_ SG_ 964 PCS_usageId "Usage ID portion of component hardware ID as reported by application";
CM_ SG_ 964 PCS_subUsageId "Sub-usage ID portion of component hardware ID as reported by application";
CM_ SG_ 964 PCS_platformType "Power conversion system (on-board charger and DC-DC converter): platform type";
CM_ SG_ 964 PCS_appCrc "Power conversion system (on-board charger and DC-DC converter): app crc";
CM_ SG_ 964 PCS_cpu2AppCrc "Power conversion system (on-board charger and DC-DC converter): cpu2 app crc";
CM_ SG_ 964 PCS_appGitHash "Power conversion system (on-board charger and DC-DC converter): app git hash";
CM_ SG_ 964 PCS_bootGitHash "Power conversion system (on-board charger and DC-DC converter): boot git hash";
CM_ SG_ 964 PCS_bootUdsProtoVersion "Power conversion system (on-board charger and DC-DC converter): boot uds proto version";
CM_ SG_ 964 PCS_bootCrc "Power conversion system (on-board charger and DC-DC converter): boot crc";
CM_ BO_ 816 "Steering column control module message: info";
CM_ SG_ 816 SCCM_infoIndex "Steering column control module: info index";
CM_ SG_ 816 SCCM_infoBuildType "Steering column control module: info build type";
CM_ SG_ 816 SCCM_infoBuildConfigId "Steering column control module: info build config id";
CM_ SG_ 816 SCCM_infoHardwareId "Steering column control module: info hardware id";
CM_ SG_ 816 SCCM_infoComponentId "Steering column control module: info component id";
CM_ SG_ 816 SCCM_infoPcbaId "Steering column control module: info pcba id";
CM_ SG_ 816 SCCM_infoAssemblyId "Steering column control module: info assembly id";
CM_ SG_ 816 SCCM_infoUsageId "Steering column control module: info usage id";
CM_ SG_ 816 SCCM_infoSubUsageId "Steering column control module: info sub usage id";
CM_ SG_ 816 SCCM_infoPlatformType "Steering column control module: info platform type";
CM_ SG_ 816 SCCM_infoAppCrc "Steering column control module: info app crc";
CM_ SG_ 816 SCCM_infoBootSvnRev "Steering column control module: info boot svn rev";
CM_ SG_ 816 SCCM_infoBootSvnUrlHash "Steering column control module: info boot svn url hash";
CM_ SG_ 816 SCCM_infoSubcomponent1Version "Steering column control module: info subcomponent1 version";
CM_ SG_ 816 SCCM_infoAppSvnHash "Steering column control module: info app svn hash";
CM_ SG_ 816 SCCM_infoBootSvnHash "Steering column control module: info boot svn hash";
CM_ SG_ 816 SCCM_infoUdsProtoVersion "Steering column control module: info uds proto version";
CM_ SG_ 816 SCCM_infoBootCrc "Steering column control module: info boot crc";
CM_ BO_ 1657 "Touchscreen user interface computer message: ambient lighting ctrls; forwarded onto this bus by the gateway";
CM_ SG_ 1657 UI_rgbEnableState "Request to enable RGB lights";
CM_ SG_ 1657 UI_rgbEffectType "Reports the RGB light effect type.";
CM_ SG_ 1657 UI_rgbBrightnessLevel "Reports the requested RGB brightness level.; raw 127 = signal not available (SNA)";
CM_ SG_ 1657 UI_rgbTargetDOORFL "Target RGB control for front left door";
CM_ SG_ 1657 UI_rgbTargetDOORFR "Target RGB control for the front right door";
CM_ SG_ 1657 UI_rgbTargetDOORRL "Target RGB control for rear left door";
CM_ SG_ 1657 UI_rgbTargetDOORRR "Target RGB control for the rear right door";
CM_ SG_ 1657 UI_rgbTargetIPFL "Reports control for RGB lighting for the front left instrument panel.";
CM_ SG_ 1657 UI_rgbTargetIPFR "Reports control for RGB lighting for the front right instrument panel.";
CM_ BO_ 819 "Touchscreen user interface computer message: charge request; forwarded onto this bus by the gateway";
CM_ SG_ 819 UI_openChargePortDoorRequest "Request to open charge port.";
CM_ SG_ 819 UI_closeChargePortDoorRequest "Request to close charge port.";
CM_ SG_ 819 UI_chargeEnableRequest "Charging request initiated";
CM_ SG_ 819 UI_acChargeCurrentLimit "UI charging line current request; raw 127 = signal not available (SNA)";
CM_ SG_ 819 UI_chargeTerminationPct "Charge Termination Limit Percent";
CM_ SG_ 819 UI_scheduledDepartureEnabled "Reports scheduled departure feature enablement.";
CM_ SG_ 819 UI_chargePortLatchRequest "Request to engage or disengage the latch.";
CM_ SG_ 819 UI_cpInletHeaterRequest "Enable charge port inlet heater";
CM_ BO_ 991 "Touchscreen user interface computer message: status2; forwarded onto this bus by the gateway";
CM_ SG_ 991 UI_userActivity "Indicates user interaction with the center display";
CM_ SG_ 991 UI_activeTouchPoints "Quantity of active touch points on the Center Display";
CM_ SG_ 991 UI_linkState "Connectivity link state";
CM_ SG_ 991 UI_autopilotSentryRequest "whether AP sentry mode should be enabled";
CM_ SG_ 991 UI_mobileAppConnected "Reports if Web Real-Time Communication (WebRTC) connection is connected while summon screen is open on the mobile app.";
CM_ SG_ 991 UI_autoshiftDRState "Reports the User Interface (UI) autoshift Drive/Reverse state.";
CM_ SG_ 991 UI_wifiBtModuleType "Reports the type of Wi-Fi and Bluetooth (BT) module.";
CM_ SG_ 991 UI_selfParkState "Reports the auto park state changes.; raw 255 = signal not available (SNA)";
CM_ SG_ 991 UI_summonDeviceIndex "Reports which device is being used to control summon.";
CM_ BO_ 663 "Touchscreen user interface computer message: suspension control; forwarded onto this bus by the gateway";
CM_ SG_ 663 UI_adaptiveRideRequest "UI customer adaptive ride request for air suspension.";
CM_ SG_ 663 UI_geofenceLevelingRequest "Geofence level request from customer; raw 5 = signal not available (SNA)";
CM_ BO_ 947 "Touchscreen user interface computer message: vehicle control2; forwarded onto this bus by the gateway";
CM_ SG_ 947 UI_gloveboxRequest "UI request to open the glovebox";
CM_ SG_ 947 UI_trunkRequest "Rear trunk request";
CM_ SG_ 947 UI_PINToDriveEnabled "UI customer level request to pin to drive enabled.";
CM_ SG_ 947 UI_PINToDrivePassed "UI customer level request to enable drive with pin passed.";
CM_ SG_ 947 UI_disableMirrorAutoDim "Request to disable side and rear-view mirror auto dim";
CM_ SG_ 947 UI_lightSwitch "Headlight mode; raw 4 = signal not available (SNA)";
CM_ SG_ 947 UI_readyToAddKey "Ready to add key";
CM_ SG_ 947 UI_alarmTriggerRequest "Alarm activation request from UI";
CM_ SG_ 947 UI_displayOnForUser "User is present";
CM_ SG_ 947 UI_BLEPushNotificationRequest "Reports that the User Interface (UI) wants to talk to a phone and Vehicle Controller Security (VCSEC) should let all connected phones know.";
CM_ SG_ 947 UI_keepAutopilotAwake "Reports the request for Vehicle Controller (VC) to keep autopilot awake.";
CM_ SG_ 947 UI_batteryPreconditioningRequest "Requests battery preconditioning.";
CM_ SG_ 947 UI_autopilotPowerStateRequest "Requests different power states from autopilot ECU depending on feature usage.";
CM_ SG_ 947 UI_autoRollWindowsOnLockEnable "UI customer level request to enable auto-roll windows on lock";
CM_ SG_ 947 UI_steeringWheelHeatReq "Request to enable steering wheel heater";
CM_ SG_ 947 UI_disableHorn "Request to disable horn";
CM_ SG_ 947 UI_frontLeftSeatFanReq "Request for front left seat ventilation";
CM_ SG_ 947 UI_frontRightSeatAutoClimateReq "UI setting to enable auto seat heating and cooling for front right seat";
CM_ SG_ 947 UI_frontRightSeatFanReq "Request for front left seat ventilation";
CM_ SG_ 947 UI_frontLeftSeatAutoClimateReq "UI setting to enable auto seat heating and cooling for front left seat";
CM_ SG_ 947 UI_wiperHeaterReq "UI request to enable the wiper heater";
CM_ SG_ 947 UI_silentAlarm "Signal indicating alarms should be silenced";
CM_ BO_ 609 "Front body controller message: 12 v battery status";
CM_ SG_ 609 VCFRONT_12VBatteryStatusIndex "Front body controller: 12 v battery status index";
CM_ SG_ 609 VCFRONT_good12VforUpdate "Indicates the Low Voltage (LV) battery health as it pertains to permitting an Over-The-Air (OTA) update.";
CM_ SG_ 609 VCFRONT_LVLoadRequest "Controls the loading of the Low Voltage (LV) battery for diagnostic purposes.";
CM_ SG_ 609 VCFRONT_12VBatteryStatusCounter "Front body controller: 12 v battery status counter";
CM_ SG_ 609 VCFRONT_12VBatteryStatusChecksum "Front body controller: 12 v battery status checksum";
CM_ SG_ 609 VCFRONT_batterySupportRequest "Reports the request to the Power Conversion System (PCS) to supply power to the Low Voltage (LV) battery.";
CM_ SG_ 609 VCFRONT_batterySMState "Reports the Low Voltage (LV) battery maintenance state machine state.";
CM_ SG_ 609 VCFRONT_eFuseRecoveryStateDBG "Reports the state of the Low Voltage (LV) battery eFuse recovery state machine.";
CM_ SG_ 609 VCFRONT_batteryLINScheduleDBG "Front body controller: battery LIN schedule DBG; raw 7 = signal not available (SNA)";
CM_ SG_ 609 VCFRONT_resistanceEstimationTest "Front body controller: resistance estimation test counter";
CM_ SG_ 609 VCFRONT_IBSCurrent "Electrical current into the 12V battery";
CM_ SG_ 609 VCFRONT_IBSVoltage "Voltage of the 12V battery; raw 4095 = signal not available (SNA)";
CM_ SG_ 609 VCFRONT_reverseBatteryFault "Indicates a fault on the reverse battery eFuse.";
CM_ SG_ 609 VCFRONT_LVBatterySupported "Indicates whether the Low Voltage (LV) battery is being supported.";
CM_ SG_ 609 VCFRONT_LVBatteryCannotSupportVe "Front body controller: LV battery cannot support vehicle";
CM_ SG_ 609 VCFRONT_goodTemp12VforUpdate "Front body controller: good temp12 vfor update";
CM_ SG_ 609 VCFRONT_12VBatteryTargetVoltage "Reports the target Low Voltage (LV) battery voltage.";
CM_ SG_ 609 VCFRONT_IBSTemperature "Front body controller: IBS temperature; raw 2047 = signal not available (SNA)";
CM_ SG_ 609 VCFRONT_currentSensorMismatchLea "Front body controller: current sensor mismatch leaky bkt pct DBG";
CM_ SG_ 609 VCFRONT_LVBatteryEnergyRemaining "Reports the percentage of energy remaining in the Low Voltage (LV) battery.";
CM_ SG_ 609 VCFRONT_LVBatteryStatusForDrive "Indicates the Low Voltage (LV) battery health status as it pertains to drive readiness. May trigger a Graceful Power Off (GPO) and block drive.";
CM_ SG_ 609 VCFRONT_LVBatteryType "Reports the type of Low Voltage (LV) battery that the firmware is configured for.";
CM_ SG_ 609 VCFRONT_resistanceEstimationNeed "Indication that the conditions which require a resistance estimation test to be performed have been met";
CM_ SG_ 609 VCFRONT_IBSVoltageFiltered "Measures the filtered voltage of the Low Voltage (LV) bus.; raw 16383 = signal not available (SNA)";
CM_ SG_ 609 VCFRONT_LVBMS_LVBusVoltageSource "Reports the source of the Low Voltage (LV) bus voltage used for the Low Voltage Battery Management System (LVBMS).";
CM_ SG_ 609 VCFRONT_LVBMS_LVPackCurrentSourc "Reports the source of the Low Voltage (LV) pack current used for LV battery charge regulation.";
CM_ SG_ 609 VCFRONT_LVBatterySupportRqrdTrig "Reports what caused the Low Voltage (LV) battery support required trigger when the vehicle wakes to charge.";
CM_ SG_ 609 VCFRONT_goodForPCSPowerCycleLeak "Front body controller: good for PCS power cycle leaky bkt DBG";
CM_ SG_ 609 VCFRONT_LVBusControlsFutile "Indicates that a required condition is not met for the Low Voltage (LV) bus controllers to operate properly.";
CM_ SG_ 609 VCFRONT_resistanceEstimatio_0001 "Front body controller: resistance estimation test valid";
CM_ SG_ 609 VCFRONT_resistanceEstimatio_0002 "Front body controller: resistance estimation tests expended";
CM_ SG_ 609 VCFRONT_goodLVChargeForUpdate "Indicates that the Low Voltage (LV) battery charge is sufficient to permit an Over-The-Air (OTA) update.";
CM_ SG_ 609 VCFRONT_opportunisticDCRTestNeed "Front body controller: opportunistic DCR test needed";
CM_ SG_ 609 VCFRONT_voltageProfile "Indicates which voltage profile is used to support the 12V battery";
CM_ SG_ 609 VCFRONT_IBSAmpHours "Measures the energy state of the Low Voltage (LV) battery in amp hours.";
CM_ SG_ 609 VCFRONT_IBSVoltageRawDBG "Front body controller: IBS voltage raw DBG; raw 16383 = signal not available (SNA)";
CM_ SG_ 609 VCFRONT_LVBatteryLINCommsDetecte "Front body controller: LV battery LIN comms detected DBG";
CM_ SG_ 609 VCFRONT_voltageSensorMismatchLea "Front body controller: voltage sensor mismatch leaky bkt pct DBG";
CM_ SG_ 609 VCFRONT_LVBatteryFctryLimOverrid "Front body controller: LV battery fctry lim override ok";
CM_ SG_ 609 VCFRONT_LVBatterySPICommsDetecte "Front body controller: LV battery SPI comms detected DBG";
CM_ SG_ 609 VCFRONT_targetCurrent "Reports the target current set by the Low Voltage Battery Management System (LVBMS).";
CM_ SG_ 609 VCFRONT_PCSMia "Indicates that the Power Conversion System (PCS) is not communicating on CAN.";
CM_ SG_ 609 VCFRONT_chargeNeeded "Indicates that the Low Voltage (LV) battery needs to be charged.";
CM_ SG_ 609 VCFRONT_voltageControlLoopIntegr "Front body controller: voltage control loop integration val";
CM_ SG_ 609 VCFRONT_currentControlLoopIntegr "Front body controller: current control loop integration val";
CM_ BO_ 1801 "Front body controller message: logging0point1 hz";
CM_ SG_ 1801 VCFRONT_logging0point1HzIndex "Front body controller: logging0point1 hz index";
CM_ SG_ 1801 VC_hcmlFactoryOfOrigin "Tier 1 supplier (Hella) factory of origin of the left headlamp";
CM_ SG_ 1801 VC_hcmlHellaPartNumberStatus "Front body controller: hcml hella part number status";
CM_ SG_ 1801 VC_hcmlHellaPartNumber "Value of the Hella Part Number written into EEPROM in the left headlamp";
CM_ SG_ 1801 VC_hcmlCurrentBinMappingType "Front body controller: hcml current bin mapping type";
CM_ SG_ 1801 VC_hcmlCurrentBin0Value "Front body controller: hcml current bin0 value; raw 0 = signal not available (SNA)";
CM_ SG_ 1801 VC_hcmlCurrentBin1Value "Front body controller: hcml current bin1 value; raw 0 = signal not available (SNA)";
CM_ SG_ 1801 VC_hcmlCurrentBin2Value "Front body controller: hcml current bin2 value; raw 0 = signal not available (SNA)";
CM_ SG_ 1801 VC_hcmlCurrentBin3Value "Front body controller: hcml current bin3 value; raw 0 = signal not available (SNA)";
CM_ SG_ 1801 VC_hcmlCurrentBin4Value "Front body controller: hcml current bin4 value; raw 0 = signal not available (SNA)";
CM_ SG_ 1801 VC_hcmlCurrentBin5Value "Front body controller: hcml current bin5 value; raw 0 = signal not available (SNA)";
CM_ SG_ 1801 VC_hcmlRegionAndSide "Left headlamp EEPROM region and side; raw 0 = signal not available (SNA)";
CM_ SG_ 1801 VC_hcmrFactoryOfOrigin "Tier 1 supplier (Hella) factory of origin of the right headlamp";
CM_ SG_ 1801 VC_hcmrHellaPartNumberStatus "Front body controller: hcmr hella part number status";
CM_ SG_ 1801 VC_hcmrHellaPartNumber "Value of the Hella Part Number written into EEPROM in the right headlamp";
CM_ SG_ 1801 VC_hcmrCurrentBinMappingType "Front body controller: hcmr current bin mapping type";
CM_ SG_ 1801 VC_hcmrCurrentBin0Value "Front body controller: hcmr current bin0 value; raw 0 = signal not available (SNA)";
CM_ SG_ 1801 VC_hcmrCurrentBin1Value "Front body controller: hcmr current bin1 value; raw 0 = signal not available (SNA)";
CM_ SG_ 1801 VC_hcmrCurrentBin2Value "Front body controller: hcmr current bin2 value; raw 0 = signal not available (SNA)";
CM_ SG_ 1801 VC_hcmrCurrentBin3Value "Front body controller: hcmr current bin3 value; raw 0 = signal not available (SNA)";
CM_ SG_ 1801 VC_hcmrCurrentBin4Value "Front body controller: hcmr current bin4 value; raw 0 = signal not available (SNA)";
CM_ SG_ 1801 VC_hcmrCurrentBin5Value "Front body controller: hcmr current bin5 value; raw 0 = signal not available (SNA)";
CM_ SG_ 1801 VC_hcmrRegionAndSide "Right headlamp EEPROM region and side; raw 0 = signal not available (SNA)";
CM_ BO_ 897 "Front body controller message: logging1 hz";
CM_ SG_ 897 VCFRONT_logging1HzIndex "Front body controller: logging1 hz index";
CM_ SG_ 897 VCFRONT_batteryDischArbState "Front body controller: battery disch arb state";
CM_ BO_ 957 "Front body controller message: parked energy loss";
CM_ SG_ 957 VCFRONT_energyLossIndex "Front body controller: energy loss index";
CM_ SG_ 957 VCFRONT_userEnergyLossSinceDrive "Energy loss due to user interaction since last drive";
CM_ SG_ 957 VCFRONT_preconditioningEner_0001 "Energy loss due to preconditioning since last drive";
CM_ SG_ 957 VCFRONT_cabinOverheatEnergy_0001 "Energy loss due to cabin overheat protection since last drive";
CM_ SG_ 957 VCFRONT_mobileAppEnergyLoss_0001 "Energy loss due to mobile app interaction since last drive";
CM_ SG_ 957 VCFRONT_summonStandbyEnergy_0001 "Energy loss due to summon standby since last drive";
CM_ SG_ 957 VCFRONT_sentryModeEnergyLos_0001 "Energy loss due to sentry mode since last drive";
CM_ SG_ 957 VCFRONT_backgroundEnergyLos_0001 "Energy loss due to background vehicle op since last drive";
CM_ SG_ 957 VCFRONT_evapDryingEnergyLos_0001 "Energy loss due to evap drying since last drive";
CM_ SG_ 957 VCFRONT_userEnergyLossSinceCharg "Energy loss due to user interaction since last charge";
CM_ SG_ 957 VCFRONT_preconditioningEnergyLos "Energy loss due to preconditioning since last charge";
CM_ SG_ 957 VCFRONT_cabinOverheatEnergyLossS "Energy loss due to cabin overheat protection since last charge";
CM_ SG_ 957 VCFRONT_mobileAppEnergyLossSince "Energy loss due to mobile app interaction since last charge";
CM_ SG_ 957 VCFRONT_summonStandbyEnergyLossS "Energy loss due to summon standby since last charge";
CM_ SG_ 957 VCFRONT_sentryModeEnergyLossSinc "Energy loss due to sentry mode since last charge";
CM_ SG_ 957 VCFRONT_backgroundEnergyLossSinc "Energy loss due to background vehicle op since last charge";
CM_ SG_ 957 VCFRONT_evapDryingEnergyLossSinc "Energy loss due to evap drying since last charge";
BA_DEF_ "BusType" STRING;
BA_DEF_ "DBName" STRING;
BA_DEF_ "Baudrate" INT 0 1000000;
BA_DEF_ "BaudrateCANFD" INT 0 16000000;
BA_DEF_ "Manufacturer" STRING;
BA_DEF_ "FirmwareVersion" STRING;
BA_DEF_ "VehicleModel" STRING;
BA_DEF_ BU_ "ECU" STRING;
BA_DEF_ BO_ "GenMsgCycleTime" INT 0 3600000;
BA_DEF_ BO_ "GenMsgSendType" ENUM "Cyclic","NotUsed","NotUsed","NotUsed","NotUsed","NotUsed","NotUsed","IfActive","NoMsgSendType","NotUsed";
BA_DEF_ BO_ "VFrameFormat" ENUM "StandardCAN","ExtendedCAN","reserved","J1939PG","reserved","reserved","reserved","reserved","reserved","reserved","reserved","reserved","reserved","reserved","StandardCAN_FD","ExtendedCAN_FD";
BA_DEF_ BO_ "CANFD_BRS" ENUM "0","1";
BA_DEF_ SG_ "GenSigSNA" STRING;
BA_DEF_ SG_ "SystemSignalLongSymbol" STRING;
BA_DEF_ SG_ "Confidence" ENUM "validated","plausible","layout-only","contradicted";
BA_DEF_DEF_ "BusType" "CAN";
BA_DEF_DEF_ "DBName" "";
BA_DEF_DEF_ "Baudrate" 500000;
BA_DEF_DEF_ "BaudrateCANFD" 2000000;
BA_DEF_DEF_ "Manufacturer" "";
BA_DEF_DEF_ "FirmwareVersion" "";
BA_DEF_DEF_ "VehicleModel" "";
BA_DEF_DEF_ "ECU" "";
BA_DEF_DEF_ "GenMsgCycleTime" 0;
BA_DEF_DEF_ "GenMsgSendType" "NoMsgSendType";
BA_DEF_DEF_ "VFrameFormat" "StandardCAN";
BA_DEF_DEF_ "CANFD_BRS" "1";
BA_DEF_DEF_ "GenSigSNA" "";
BA_DEF_DEF_ "SystemSignalLongSymbol" "";
BA_DEF_DEF_ "Confidence" "layout-only";
BA_ "DBName" "ModelY_VEH";
BA_ "Manufacturer" "Tesla";
BA_ "FirmwareVersion" "2025.20.8";
BA_ "VehicleModel" "Model Y";
BA_ "ECU" BU_ BMS "BMS";
BA_ "ECU" BU_ CP "CP";
BA_ "ECU" BU_ DAS "DAS";
BA_ "ECU" BU_ DIF "DIF";
BA_ "ECU" BU_ GTW "GTW";
BA_ "ECU" BU_ HVP "HVP";
BA_ "ECU" BU_ ICR "ICR";
BA_ "ECU" BU_ PCS "PCS";
BA_ "ECU" BU_ SCCM "SCCM";
BA_ "ECU" BU_ VCFRONT "VCFRONT";
BA_ "ECU" BU_ VCLEFT "VCLEFT";
BA_ "ECU" BU_ VCRIGHT "VCRIGHT";
BA_ "ECU" BU_ VCSEC "VCSEC";
BA_ "GenMsgCycleTime" BO_ 1138 1000;
BA_ "GenMsgSendType" BO_ 1138 0;
BA_ "GenMsgCycleTime" BO_ 658 100;
BA_ "GenMsgSendType" BO_ 658 0;
BA_ "GenMsgCycleTime" BO_ 669 100;
BA_ "GenMsgSendType" BO_ 669 0;
BA_ "GenMsgCycleTime" BO_ 541 100;
BA_ "GenMsgSendType" BO_ 541 0;
BA_ "GenMsgCycleTime" BO_ 1001 500;
BA_ "GenMsgSendType" BO_ 1001 0;
BA_ "GenMsgCycleTime" BO_ 634 100;
BA_ "GenMsgSendType" BO_ 634 0;
BA_ "GenMsgCycleTime" BO_ 784 10000;
BA_ "GenMsgSendType" BO_ 784 0;
BA_ "GenMsgCycleTime" BO_ 941 10000;
BA_ "GenMsgSendType" BO_ 941 0;
BA_ "GenMsgCycleTime" BO_ 964 1000;
BA_ "GenMsgSendType" BO_ 964 0;
BA_ "GenMsgCycleTime" BO_ 816 1000;
BA_ "GenMsgSendType" BO_ 816 0;
BA_ "GenMsgCycleTime" BO_ 1657 500;
BA_ "GenMsgSendType" BO_ 1657 0;
BA_ "GenMsgCycleTime" BO_ 819 500;
BA_ "GenMsgSendType" BO_ 819 0;
BA_ "GenMsgCycleTime" BO_ 991 500;
BA_ "GenMsgSendType" BO_ 991 0;
BA_ "GenMsgCycleTime" BO_ 663 500;
BA_ "GenMsgSendType" BO_ 663 0;
BA_ "GenMsgCycleTime" BO_ 947 500;
BA_ "GenMsgSendType" BO_ 947 0;
BA_ "GenMsgCycleTime" BO_ 609 16;
BA_ "GenMsgSendType" BO_ 609 0;
BA_ "GenMsgCycleTime" BO_ 1801 322;
BA_ "GenMsgSendType" BO_ 1801 0;
BA_ "GenMsgCycleTime" BO_ 897 38;
BA_ "GenMsgSendType" BO_ 897 0;
BA_ "GenMsgCycleTime" BO_ 957 1000;
BA_ "GenMsgSendType" BO_ 957 0;
BA_ "Confidence" SG_ 1138 BMS_voltageRegCurrentTarget 1;
BA_ "Confidence" SG_ 1138 BMS_vehicleChargeDcCurrentLimit 1;
BA_ "Confidence" SG_ 1138 BMS_chargeCurrentLimitMode 1;
BA_ "Confidence" SG_ 1138 BMS_timeToFinishHeatForCharge 1;
BA_ "GenSigSNA" SG_ 1138 BMS_timeToFinishHeatForCharge "127";
BA_ "Confidence" SG_ 658 BMS_userChargeCurrentLimitMode 1;
BA_ "Confidence" SG_ 669 CP_evseOutputDcCurrent 0;
BA_ "Confidence" SG_ 669 CP_evseOutputDcVoltage 0;
BA_ "Confidence" SG_ 669 CP_evseOutputDcCurrentStale 0;
BA_ "Confidence" SG_ 541 CP_evseAccept 0;
BA_ "Confidence" SG_ 541 CP_evseRequest 0;
BA_ "Confidence" SG_ 541 CP_proximity 0;
BA_ "GenSigSNA" SG_ 541 CP_proximity "0";
BA_ "Confidence" SG_ 541 CP_pilot 0;
BA_ "GenSigSNA" SG_ 541 CP_pilot "7";
BA_ "Confidence" SG_ 541 CP_digitalCommsEstablished 0;
BA_ "Confidence" SG_ 541 CP_pilotCurrent 0;
BA_ "Confidence" SG_ 541 CP_cableType 0;
BA_ "GenSigSNA" SG_ 541 CP_cableType "4";
BA_ "Confidence" SG_ 541 CP_iecPilotState 0;
BA_ "GenSigSNA" SG_ 541 CP_iecPilotState "9";
BA_ "Confidence" SG_ 541 CP_plcSupported 0;
BA_ "Confidence" SG_ 541 CP_cableCurrentLimit 0;
BA_ "Confidence" SG_ 541 CP_teslaSwcanState 0;
BA_ "Confidence" SG_ 541 CP_evseChargeType_UI 0;
BA_ "Confidence" SG_ 541 CP_gbState 0;
BA_ "Confidence" SG_ 541 CP_gbdcStopChargeReason 0;
BA_ "Confidence" SG_ 541 CP_gbdcFailureReason 0;
BA_ "Confidence" SG_ 541 CP_gbdcChargeAttempts 0;
BA_ "Confidence" SG_ 541 CP_acChargeState 0;
BA_ "Confidence" SG_ 541 CP_teslaDcState 1;
BA_ "Confidence" SG_ 1001 DAS_headlightRequest 0;
BA_ "Confidence" SG_ 1001 DAS_hazardLightRequest 0;
BA_ "GenSigSNA" SG_ 1001 DAS_hazardLightRequest "3";
BA_ "Confidence" SG_ 1001 DAS_wiperSpeed 0;
BA_ "Confidence" SG_ 1001 DAS_turnIndicatorRequest 0;
BA_ "Confidence" SG_ 1001 DAS_highLowBeamDecision 0;
BA_ "GenSigSNA" SG_ 1001 DAS_highLowBeamDecision "3";
BA_ "Confidence" SG_ 1001 DAS_heaterRequest 0;
BA_ "GenSigSNA" SG_ 1001 DAS_heaterRequest "0";
BA_ "Confidence" SG_ 1001 DAS_highLowBeamOffReason 0;
BA_ "GenSigSNA" SG_ 1001 DAS_highLowBeamOffReason "5";
BA_ "Confidence" SG_ 1001 DAS_forwardCamHeaterDutyCycle 0;
BA_ "Confidence" SG_ 1001 DAS_dynamicBrakeLightRequest 0;
BA_ "Confidence" SG_ 1001 DAS_radarHeaterRequest 0;
BA_ "Confidence" SG_ 1001 DAS_ahlbOverride 0;
BA_ "Confidence" SG_ 1001 DAS_mirrorFoldRequest 0;
BA_ "GenSigSNA" SG_ 1001 DAS_mirrorFoldRequest "3";
BA_ "Confidence" SG_ 1001 DAS_wiperWashRequest 0;
BA_ "Confidence" SG_ 1001 DAS_ulcConfirmationRequestActive 0;
BA_ "Confidence" SG_ 1001 DAS_overrideWiperSetting 0;
BA_ "Confidence" SG_ 1001 DAS_autoWiperState 0;
BA_ "GenSigSNA" SG_ 1001 DAS_autoWiperState "5";
BA_ "Confidence" SG_ 1001 DAS_turnIndicatorRequestReason 0;
BA_ "Confidence" SG_ 1001 DAS_forwardRadarPowerRequest 0;
BA_ "Confidence" SG_ 1001 DAS_driverDomeLightRequest 0;
BA_ "Confidence" SG_ 1001 DAS_drivePowerStateRequest 0;
BA_ "Confidence" SG_ 1001 DAS_enableIcrDataCollection 0;
BA_ "Confidence" SG_ 1001 DAS_rPillarCamHeaterDutyCycle 0;
BA_ "Confidence" SG_ 1001 DAS_adaptiveHighBeamIsFaulted 0;
BA_ "Confidence" SG_ 1001 DAS_restrictDoorReleaseLeft 0;
BA_ "Confidence" SG_ 1001 DAS_restrictDoorReleaseRight 0;
BA_ "Confidence" SG_ 1001 DAS_bodyControlsCounter 0;
BA_ "Confidence" SG_ 1001 DAS_bodyControlsChecksum 0;
BA_ "Confidence" SG_ 634 DIF_hvStatusChecksum 0;
BA_ "Confidence" SG_ 634 DIF_hvStatusCounter 0;
BA_ "Confidence" SG_ 634 DIF_hvilCurrent 0;
BA_ "Confidence" SG_ 634 DIF_hvilCmVoltage 0;
BA_ "Confidence" SG_ 634 DIF_hvilStatus 0;
BA_ "GenSigSNA" SG_ 634 DIF_hvilStatus "3";
BA_ "Confidence" SG_ 634 DIF_hvilSupplyState 0;
BA_ "Confidence" SG_ 634 DIF_activeDischargeCtrl 0;
BA_ "Confidence" SG_ 634 DIF_activeDischargeStatus 0;
BA_ "Confidence" SG_ 634 DIF_vBat 0;
BA_ "Confidence" SG_ 634 DIF_vBatQF 0;
BA_ "Confidence" SG_ 634 DIF_powerStageSafeState 0;
BA_ "Confidence" SG_ 634 DIF_fluxState 0;
BA_ "Confidence" SG_ 634 DIF_vBusDiag 0;
BA_ "Confidence" SG_ 634 DIF_gateDriveState 0;
BA_ "Confidence" SG_ 784 HVP_infoIndex 1;
BA_ "Confidence" SG_ 784 HVP_buildType 0;
BA_ "Confidence" SG_ 784 HVP_buildConfigId 0;
BA_ "Confidence" SG_ 784 HVP_hardwareId 0;
BA_ "Confidence" SG_ 784 HVP_componentId 0;
BA_ "Confidence" SG_ 784 HVP_pcbaId 0;
BA_ "Confidence" SG_ 784 HVP_assemblyId 0;
BA_ "Confidence" SG_ 784 HVP_usageId 0;
BA_ "Confidence" SG_ 784 HVP_subUsageId 0;
BA_ "Confidence" SG_ 784 HVP_platformType 0;
BA_ "Confidence" SG_ 784 HVP_appCrc 0;
BA_ "Confidence" SG_ 784 HVP_appGitHash 0;
BA_ "Confidence" SG_ 784 HVP_bootGitHash 0;
BA_ "Confidence" SG_ 784 HVP_bootUdsProtoVersion 0;
BA_ "Confidence" SG_ 784 HVP_bootCrc 0;
BA_ "Confidence" SG_ 941 ICR_infoIndex 1;
BA_ "Confidence" SG_ 941 ICR_infoBuildType 0;
BA_ "Confidence" SG_ 941 ICR_infoPcbaId 0;
BA_ "Confidence" SG_ 941 ICR_infoAssemblyId 0;
BA_ "Confidence" SG_ 941 ICR_infoUsageId 0;
BA_ "Confidence" SG_ 941 ICR_infoAppCrc 0;
BA_ "Confidence" SG_ 941 ICR_infoBoardPartNumber17 0;
BA_ "Confidence" SG_ 941 ICR_infoBoardPartNumber814 0;
BA_ "Confidence" SG_ 941 ICR_infoBoardPartNumber1520 0;
BA_ "Confidence" SG_ 964 PCS_infoIndex 1;
BA_ "Confidence" SG_ 964 PCS_buildType 0;
BA_ "Confidence" SG_ 964 PCS_buildConfigId 0;
BA_ "Confidence" SG_ 964 PCS_hardwareId 0;
BA_ "Confidence" SG_ 964 PCS_componentId 0;
BA_ "Confidence" SG_ 964 PCS_pcbaId 0;
BA_ "Confidence" SG_ 964 PCS_assemblyId 0;
BA_ "Confidence" SG_ 964 PCS_usageId 0;
BA_ "Confidence" SG_ 964 PCS_subUsageId 0;
BA_ "Confidence" SG_ 964 PCS_platformType 0;
BA_ "Confidence" SG_ 964 PCS_appCrc 0;
BA_ "Confidence" SG_ 964 PCS_cpu2AppCrc 0;
BA_ "Confidence" SG_ 964 PCS_appGitHash 0;
BA_ "Confidence" SG_ 964 PCS_bootGitHash 0;
BA_ "Confidence" SG_ 964 PCS_bootUdsProtoVersion 0;
BA_ "Confidence" SG_ 964 PCS_bootCrc 0;
BA_ "Confidence" SG_ 816 SCCM_infoIndex 1;
BA_ "Confidence" SG_ 816 SCCM_infoBuildType 0;
BA_ "Confidence" SG_ 816 SCCM_infoBuildConfigId 0;
BA_ "Confidence" SG_ 816 SCCM_infoHardwareId 0;
BA_ "Confidence" SG_ 816 SCCM_infoComponentId 0;
BA_ "Confidence" SG_ 816 SCCM_infoPcbaId 0;
BA_ "Confidence" SG_ 816 SCCM_infoAssemblyId 0;
BA_ "Confidence" SG_ 816 SCCM_infoUsageId 0;
BA_ "Confidence" SG_ 816 SCCM_infoSubUsageId 0;
BA_ "Confidence" SG_ 816 SCCM_infoPlatformType 0;
BA_ "Confidence" SG_ 816 SCCM_infoBootSvnRev 0;
BA_ "Confidence" SG_ 816 SCCM_infoBootSvnUrlHash 0;
BA_ "Confidence" SG_ 816 SCCM_infoSubcomponent1Version 0;
BA_ "Confidence" SG_ 816 SCCM_infoAppSvnHash 0;
BA_ "Confidence" SG_ 816 SCCM_infoBootSvnHash 0;
BA_ "Confidence" SG_ 816 SCCM_infoUdsProtoVersion 0;
BA_ "Confidence" SG_ 816 SCCM_infoBootCrc 0;
BA_ "Confidence" SG_ 1657 UI_rgbEnableState 0;
BA_ "Confidence" SG_ 1657 UI_rgbEffectType 0;
BA_ "Confidence" SG_ 1657 UI_rgbBrightnessLevel 0;
BA_ "GenSigSNA" SG_ 1657 UI_rgbBrightnessLevel "127";
BA_ "Confidence" SG_ 1657 UI_rgbTargetDOORFL 0;
BA_ "Confidence" SG_ 1657 UI_rgbTargetDOORFR 0;
BA_ "Confidence" SG_ 1657 UI_rgbTargetDOORRL 0;
BA_ "Confidence" SG_ 1657 UI_rgbTargetDOORRR 0;
BA_ "Confidence" SG_ 1657 UI_rgbTargetIPFL 0;
BA_ "Confidence" SG_ 1657 UI_rgbTargetIPFR 0;
BA_ "Confidence" SG_ 819 UI_openChargePortDoorRequest 0;
BA_ "Confidence" SG_ 819 UI_closeChargePortDoorRequest 0;
BA_ "Confidence" SG_ 819 UI_chargeEnableRequest 0;
BA_ "Confidence" SG_ 819 UI_acChargeCurrentLimit 0;
BA_ "GenSigSNA" SG_ 819 UI_acChargeCurrentLimit "127";
BA_ "Confidence" SG_ 819 UI_chargeTerminationPct 0;
BA_ "Confidence" SG_ 819 UI_scheduledDepartureEnabled 0;
BA_ "Confidence" SG_ 819 UI_chargePortLatchRequest 0;
BA_ "Confidence" SG_ 819 UI_cpInletHeaterRequest 0;
BA_ "Confidence" SG_ 991 UI_userActivity 0;
BA_ "Confidence" SG_ 991 UI_activeTouchPoints 0;
BA_ "Confidence" SG_ 991 UI_linkState 0;
BA_ "Confidence" SG_ 991 UI_autopilotSentryRequest 0;
BA_ "Confidence" SG_ 991 UI_mobileAppConnected 0;
BA_ "Confidence" SG_ 991 UI_autoshiftDRState 0;
BA_ "Confidence" SG_ 991 UI_wifiBtModuleType 0;
BA_ "Confidence" SG_ 991 UI_selfParkState 0;
BA_ "GenSigSNA" SG_ 991 UI_selfParkState "255";
BA_ "Confidence" SG_ 991 UI_summonDeviceIndex 0;
BA_ "Confidence" SG_ 663 UI_adaptiveRideRequest 0;
BA_ "Confidence" SG_ 663 UI_geofenceLevelingRequest 0;
BA_ "GenSigSNA" SG_ 663 UI_geofenceLevelingRequest "5";
BA_ "Confidence" SG_ 947 UI_gloveboxRequest 0;
BA_ "Confidence" SG_ 947 UI_trunkRequest 0;
BA_ "Confidence" SG_ 947 UI_PINToDriveEnabled 0;
BA_ "Confidence" SG_ 947 UI_PINToDrivePassed 0;
BA_ "Confidence" SG_ 947 UI_disableMirrorAutoDim 0;
BA_ "Confidence" SG_ 947 UI_lightSwitch 0;
BA_ "GenSigSNA" SG_ 947 UI_lightSwitch "4";
BA_ "Confidence" SG_ 947 UI_readyToAddKey 0;
BA_ "Confidence" SG_ 947 UI_alarmTriggerRequest 0;
BA_ "Confidence" SG_ 947 UI_displayOnForUser 0;
BA_ "Confidence" SG_ 947 UI_BLEPushNotificationRequest 0;
BA_ "Confidence" SG_ 947 UI_keepAutopilotAwake 0;
BA_ "Confidence" SG_ 947 UI_batteryPreconditioningRequest 0;
BA_ "Confidence" SG_ 947 UI_autopilotPowerStateRequest 0;
BA_ "Confidence" SG_ 947 UI_autoRollWindowsOnLockEnable 0;
BA_ "Confidence" SG_ 947 UI_steeringWheelHeatReq 0;
BA_ "Confidence" SG_ 947 UI_disableHorn 0;
BA_ "Confidence" SG_ 947 UI_frontLeftSeatFanReq 0;
BA_ "Confidence" SG_ 947 UI_frontRightSeatAutoClimateReq 0;
BA_ "Confidence" SG_ 947 UI_frontRightSeatFanReq 0;
BA_ "Confidence" SG_ 947 UI_frontLeftSeatAutoClimateReq 0;
BA_ "Confidence" SG_ 947 UI_wiperHeaterReq 0;
BA_ "Confidence" SG_ 947 UI_silentAlarm 0;
BA_ "Confidence" SG_ 609 VCFRONT_12VBatteryStatusIndex 1;
BA_ "Confidence" SG_ 609 VCFRONT_good12VforUpdate 0;
BA_ "Confidence" SG_ 609 VCFRONT_LVLoadRequest 0;
BA_ "Confidence" SG_ 609 VCFRONT_12VBatteryStatusCounter 0;
BA_ "Confidence" SG_ 609 VCFRONT_12VBatteryStatusChecksum 0;
BA_ "Confidence" SG_ 609 VCFRONT_batterySupportRequest 0;
BA_ "Confidence" SG_ 609 VCFRONT_batterySMState 0;
BA_ "Confidence" SG_ 609 VCFRONT_eFuseRecoveryStateDBG 0;
BA_ "Confidence" SG_ 609 VCFRONT_batteryLINScheduleDBG 0;
BA_ "GenSigSNA" SG_ 609 VCFRONT_batteryLINScheduleDBG "7";
BA_ "Confidence" SG_ 609 VCFRONT_resistanceEstimationTest 0;
BA_ "SystemSignalLongSymbol" SG_ 609 VCFRONT_resistanceEstimationTest "VCFRONT_resistanceEstimationTestCounter";
BA_ "Confidence" SG_ 609 VCFRONT_IBSCurrent 0;
BA_ "Confidence" SG_ 609 VCFRONT_IBSVoltage 0;
BA_ "GenSigSNA" SG_ 609 VCFRONT_IBSVoltage "4095";
BA_ "Confidence" SG_ 609 VCFRONT_reverseBatteryFault 0;
BA_ "Confidence" SG_ 609 VCFRONT_LVBatterySupported 0;
BA_ "Confidence" SG_ 609 VCFRONT_LVBatteryCannotSupportVe 0;
BA_ "SystemSignalLongSymbol" SG_ 609 VCFRONT_LVBatteryCannotSupportVe "VCFRONT_LVBatteryCannotSupportVehicle";
BA_ "Confidence" SG_ 609 VCFRONT_goodTemp12VforUpdate 0;
BA_ "Confidence" SG_ 609 VCFRONT_12VBatteryTargetVoltage 0;
BA_ "Confidence" SG_ 609 VCFRONT_IBSTemperature 0;
BA_ "GenSigSNA" SG_ 609 VCFRONT_IBSTemperature "2047";
BA_ "Confidence" SG_ 609 VCFRONT_currentSensorMismatchLea 0;
BA_ "SystemSignalLongSymbol" SG_ 609 VCFRONT_currentSensorMismatchLea "VCFRONT_currentSensorMismatchLeakyBktPctDBG";
BA_ "Confidence" SG_ 609 VCFRONT_LVBatteryEnergyRemaining 0;
BA_ "SystemSignalLongSymbol" SG_ 609 VCFRONT_LVBatteryEnergyRemaining "VCFRONT_LVBatteryEnergyRemainingPCT";
BA_ "Confidence" SG_ 609 VCFRONT_LVBatteryStatusForDrive 0;
BA_ "Confidence" SG_ 609 VCFRONT_LVBatteryType 0;
BA_ "Confidence" SG_ 609 VCFRONT_resistanceEstimationNeed 0;
BA_ "SystemSignalLongSymbol" SG_ 609 VCFRONT_resistanceEstimationNeed "VCFRONT_resistanceEstimationNeeded";
BA_ "Confidence" SG_ 609 VCFRONT_IBSVoltageFiltered 0;
BA_ "GenSigSNA" SG_ 609 VCFRONT_IBSVoltageFiltered "16383";
BA_ "Confidence" SG_ 609 VCFRONT_LVBMS_LVBusVoltageSource 0;
BA_ "SystemSignalLongSymbol" SG_ 609 VCFRONT_LVBMS_LVBusVoltageSource "VCFRONT_LVBMS_LVBusVoltageSourceDBG";
BA_ "Confidence" SG_ 609 VCFRONT_LVBMS_LVPackCurrentSourc 0;
BA_ "SystemSignalLongSymbol" SG_ 609 VCFRONT_LVBMS_LVPackCurrentSourc "VCFRONT_LVBMS_LVPackCurrentSourceDBG";
BA_ "Confidence" SG_ 609 VCFRONT_LVBatterySupportRqrdTrig 0;
BA_ "SystemSignalLongSymbol" SG_ 609 VCFRONT_LVBatterySupportRqrdTrig "VCFRONT_LVBatterySupportRqrdTrigger";
BA_ "Confidence" SG_ 609 VCFRONT_goodForPCSPowerCycleLeak 0;
BA_ "SystemSignalLongSymbol" SG_ 609 VCFRONT_goodForPCSPowerCycleLeak "VCFRONT_goodForPCSPowerCycleLeakyBktDBG";
BA_ "Confidence" SG_ 609 VCFRONT_LVBusControlsFutile 0;
BA_ "Confidence" SG_ 609 VCFRONT_resistanceEstimatio_0001 0;
BA_ "SystemSignalLongSymbol" SG_ 609 VCFRONT_resistanceEstimatio_0001 "VCFRONT_resistanceEstimationTestValid";
BA_ "Confidence" SG_ 609 VCFRONT_resistanceEstimatio_0002 0;
BA_ "SystemSignalLongSymbol" SG_ 609 VCFRONT_resistanceEstimatio_0002 "VCFRONT_resistanceEstimationTestsExpended";
BA_ "Confidence" SG_ 609 VCFRONT_goodLVChargeForUpdate 0;
BA_ "Confidence" SG_ 609 VCFRONT_opportunisticDCRTestNeed 0;
BA_ "SystemSignalLongSymbol" SG_ 609 VCFRONT_opportunisticDCRTestNeed "VCFRONT_opportunisticDCRTestNeeded";
BA_ "Confidence" SG_ 609 VCFRONT_voltageProfile 0;
BA_ "Confidence" SG_ 609 VCFRONT_IBSAmpHours 0;
BA_ "Confidence" SG_ 609 VCFRONT_IBSVoltageRawDBG 0;
BA_ "GenSigSNA" SG_ 609 VCFRONT_IBSVoltageRawDBG "16383";
BA_ "Confidence" SG_ 609 VCFRONT_LVBatteryLINCommsDetecte 0;
BA_ "SystemSignalLongSymbol" SG_ 609 VCFRONT_LVBatteryLINCommsDetecte "VCFRONT_LVBatteryLINCommsDetectedDBG";
BA_ "Confidence" SG_ 609 VCFRONT_voltageSensorMismatchLea 0;
BA_ "SystemSignalLongSymbol" SG_ 609 VCFRONT_voltageSensorMismatchLea "VCFRONT_voltageSensorMismatchLeakyBktPctDBG";
BA_ "Confidence" SG_ 609 VCFRONT_LVBatteryFctryLimOverrid 0;
BA_ "SystemSignalLongSymbol" SG_ 609 VCFRONT_LVBatteryFctryLimOverrid "VCFRONT_LVBatteryFctryLimOverrideOk";
BA_ "Confidence" SG_ 609 VCFRONT_LVBatterySPICommsDetecte 0;
BA_ "SystemSignalLongSymbol" SG_ 609 VCFRONT_LVBatterySPICommsDetecte "VCFRONT_LVBatterySPICommsDetectedDBG";
BA_ "Confidence" SG_ 609 VCFRONT_targetCurrent 0;
BA_ "Confidence" SG_ 609 VCFRONT_PCSMia 0;
BA_ "Confidence" SG_ 609 VCFRONT_chargeNeeded 0;
BA_ "Confidence" SG_ 609 VCFRONT_voltageControlLoopIntegr 0;
BA_ "SystemSignalLongSymbol" SG_ 609 VCFRONT_voltageControlLoopIntegr "VCFRONT_voltageControlLoopIntegrationVal";
BA_ "Confidence" SG_ 609 VCFRONT_currentControlLoopIntegr 0;
BA_ "SystemSignalLongSymbol" SG_ 609 VCFRONT_currentControlLoopIntegr "VCFRONT_currentControlLoopIntegrationVal";
BA_ "Confidence" SG_ 1801 VCFRONT_logging0point1HzIndex 1;
BA_ "Confidence" SG_ 1801 VC_hcmlFactoryOfOrigin 1;
BA_ "Confidence" SG_ 1801 VC_hcmlHellaPartNumberStatus 1;
BA_ "Confidence" SG_ 1801 VC_hcmlHellaPartNumber 1;
BA_ "Confidence" SG_ 1801 VC_hcmlCurrentBinMappingType 1;
BA_ "Confidence" SG_ 1801 VC_hcmlCurrentBin0Value 1;
BA_ "GenSigSNA" SG_ 1801 VC_hcmlCurrentBin0Value "0";
BA_ "Confidence" SG_ 1801 VC_hcmlCurrentBin1Value 1;
BA_ "GenSigSNA" SG_ 1801 VC_hcmlCurrentBin1Value "0";
BA_ "Confidence" SG_ 1801 VC_hcmlCurrentBin2Value 1;
BA_ "GenSigSNA" SG_ 1801 VC_hcmlCurrentBin2Value "0";
BA_ "Confidence" SG_ 1801 VC_hcmlCurrentBin3Value 1;
BA_ "GenSigSNA" SG_ 1801 VC_hcmlCurrentBin3Value "0";
BA_ "Confidence" SG_ 1801 VC_hcmlCurrentBin4Value 1;
BA_ "GenSigSNA" SG_ 1801 VC_hcmlCurrentBin4Value "0";
BA_ "Confidence" SG_ 1801 VC_hcmlCurrentBin5Value 1;
BA_ "GenSigSNA" SG_ 1801 VC_hcmlCurrentBin5Value "0";
BA_ "Confidence" SG_ 1801 VC_hcmlRegionAndSide 1;
BA_ "GenSigSNA" SG_ 1801 VC_hcmlRegionAndSide "0";
BA_ "Confidence" SG_ 1801 VC_hcmrFactoryOfOrigin 1;
BA_ "Confidence" SG_ 1801 VC_hcmrHellaPartNumberStatus 1;
BA_ "Confidence" SG_ 1801 VC_hcmrHellaPartNumber 1;
BA_ "Confidence" SG_ 1801 VC_hcmrCurrentBinMappingType 1;
BA_ "Confidence" SG_ 1801 VC_hcmrCurrentBin0Value 1;
BA_ "GenSigSNA" SG_ 1801 VC_hcmrCurrentBin0Value "0";
BA_ "Confidence" SG_ 1801 VC_hcmrCurrentBin1Value 1;
BA_ "GenSigSNA" SG_ 1801 VC_hcmrCurrentBin1Value "0";
BA_ "Confidence" SG_ 1801 VC_hcmrCurrentBin2Value 1;
BA_ "GenSigSNA" SG_ 1801 VC_hcmrCurrentBin2Value "0";
BA_ "Confidence" SG_ 1801 VC_hcmrCurrentBin3Value 1;
BA_ "GenSigSNA" SG_ 1801 VC_hcmrCurrentBin3Value "0";
BA_ "Confidence" SG_ 1801 VC_hcmrCurrentBin4Value 1;
BA_ "GenSigSNA" SG_ 1801 VC_hcmrCurrentBin4Value "0";
BA_ "Confidence" SG_ 1801 VC_hcmrCurrentBin5Value 1;
BA_ "GenSigSNA" SG_ 1801 VC_hcmrCurrentBin5Value "0";
BA_ "Confidence" SG_ 1801 VC_hcmrRegionAndSide 1;
BA_ "GenSigSNA" SG_ 1801 VC_hcmrRegionAndSide "0";
BA_ "Confidence" SG_ 897 VCFRONT_logging1HzIndex 1;
BA_ "Confidence" SG_ 897 VCFRONT_batteryDischArbState 1;
BA_ "Confidence" SG_ 957 VCFRONT_energyLossIndex 1;
BA_ "Confidence" SG_ 957 VCFRONT_userEnergyLossSinceDrive 0;
BA_ "Confidence" SG_ 957 VCFRONT_preconditioningEner_0001 0;
BA_ "SystemSignalLongSymbol" SG_ 957 VCFRONT_preconditioningEner_0001 "VCFRONT_preconditioningEnergyLossSinceDrive";
BA_ "Confidence" SG_ 957 VCFRONT_cabinOverheatEnergy_0001 0;
BA_ "SystemSignalLongSymbol" SG_ 957 VCFRONT_cabinOverheatEnergy_0001 "VCFRONT_cabinOverheatEnergyLossSinceDrive";
BA_ "Confidence" SG_ 957 VCFRONT_mobileAppEnergyLoss_0001 0;
BA_ "SystemSignalLongSymbol" SG_ 957 VCFRONT_mobileAppEnergyLoss_0001 "VCFRONT_mobileAppEnergyLossSinceDrive";
BA_ "Confidence" SG_ 957 VCFRONT_summonStandbyEnergy_0001 0;
BA_ "SystemSignalLongSymbol" SG_ 957 VCFRONT_summonStandbyEnergy_0001 "VCFRONT_summonStandbyEnergyLossSinceDrive";
BA_ "Confidence" SG_ 957 VCFRONT_sentryModeEnergyLos_0001 0;
BA_ "SystemSignalLongSymbol" SG_ 957 VCFRONT_sentryModeEnergyLos_0001 "VCFRONT_sentryModeEnergyLossSinceDrive";
BA_ "Confidence" SG_ 957 VCFRONT_backgroundEnergyLos_0001 0;
BA_ "SystemSignalLongSymbol" SG_ 957 VCFRONT_backgroundEnergyLos_0001 "VCFRONT_backgroundEnergyLossSinceDrive";
BA_ "Confidence" SG_ 957 VCFRONT_evapDryingEnergyLos_0001 0;
BA_ "SystemSignalLongSymbol" SG_ 957 VCFRONT_evapDryingEnergyLos_0001 "VCFRONT_evapDryingEnergyLossSinceDrive";
BA_ "Confidence" SG_ 957 VCFRONT_userEnergyLossSinceCharg 0;
BA_ "SystemSignalLongSymbol" SG_ 957 VCFRONT_userEnergyLossSinceCharg "VCFRONT_userEnergyLossSinceCharge";
BA_ "Confidence" SG_ 957 VCFRONT_preconditioningEnergyLos 0;
BA_ "SystemSignalLongSymbol" SG_ 957 VCFRONT_preconditioningEnergyLos "VCFRONT_preconditioningEnergyLossSinceCharge";
BA_ "Confidence" SG_ 957 VCFRONT_cabinOverheatEnergyLossS 0;
BA_ "SystemSignalLongSymbol" SG_ 957 VCFRONT_cabinOverheatEnergyLossS "VCFRONT_cabinOverheatEnergyLossSinceCharge";
BA_ "Confidence" SG_ 957 VCFRONT_mobileAppEnergyLossSince 0;
BA_ "SystemSignalLongSymbol" SG_ 957 VCFRONT_mobileAppEnergyLossSince "VCFRONT_mobileAppEnergyLossSinceCharge";
BA_ "Confidence" SG_ 957 VCFRONT_summonStandbyEnergyLossS 0;
BA_ "SystemSignalLongSymbol" SG_ 957 VCFRONT_summonStandbyEnergyLossS "VCFRONT_summonStandbyEnergyLossSinceCharge";
BA_ "Confidence" SG_ 957 VCFRONT_sentryModeEnergyLossSinc 0;
BA_ "SystemSignalLongSymbol" SG_ 957 VCFRONT_sentryModeEnergyLossSinc "VCFRONT_sentryModeEnergyLossSinceCharge";
BA_ "Confidence" SG_ 957 VCFRONT_backgroundEnergyLossSinc 0;
BA_ "SystemSignalLongSymbol" SG_ 957 VCFRONT_backgroundEnergyLossSinc "VCFRONT_backgroundEnergyLossSinceCharge";
BA_ "Confidence" SG_ 957 VCFRONT_evapDryingEnergyLossSinc 0;
BA_ "SystemSignalLongSymbol" SG_ 957 VCFRONT_evapDryingEnergyLossSinc "VCFRONT_evapDryingEnergyLossSinceCharge";
VAL_ 1138 BMS_chargeCurrentLimitMode 20 "CHG_LIMIT_RIPPLE_HEAT_ACTIVE" 19 "CHG_LIMIT_NEAR_HWOT_LIMIT" 18 "CHG_LIMIT_LIMP_MODE" 17 "CHG_LIMIT_MISSING_CELL" 16 "CHG_LIMIT_CAC_IMBALANCE" 15 "CHG_LIMIT_PCS_IMPLICIT" 14 "CHG_LIMIT_EVSE_IMPLICIT" 13 "CHG_LIMIT_RAMP_UP_PHASE" 12 "CHG_LIMIT_HVAC_COOLING" 11 "CHG_LIMIT_HV_CHAIN" 10 "CHG_LIMIT_CONFIG" 9 "CHG_LIMIT_TETHERING" 8 "CHG_LIMIT_LEAKY_BUCKET" 7 "CHG_LIMIT_BRICK_VOLTAGE_REG" 6 "CHG_LIMIT_BRICK_TEMP_TOO_COLD" 5 "CHG_LIMIT_BRICK_TEMP_TOO_HOT" 4 "CHG_LIMIT_BRICK_TEMP_OPTIMAL_CELL_PROFILE" 3 "CHG_LIMIT_CP" 2 "CHG_LIMIT_PCS" 1 "CHG_LIMIT_EVSE" 0 "CHG_LIMIT_NONE" ;
VAL_ 1138 BMS_timeToFinishHeatForCharge 127 "SNA" 126 "CALCULATING" ;
VAL_ 658 BMS_userChargeCurrentLimitMode 4 "USR_CHG_LIMIT_EVSE_RELOCATION_RECOMMENDED" 3 "USR_CHG_LIMIT_HIGH_SOC" 2 "USR_CHG_LIMIT_BATT_TEMP_LOW" 1 "USR_CHG_LIMIT_EVSE" 0 "USR_CHG_LIMIT_NONE" ;
VAL_ 541 CP_proximity 3 "CHG_PROXIMITY_LATCHED" 2 "CHG_PROXIMITY_UNLATCHED" 1 "CHG_PROXIMITY_DISCONNECTED" 0 "CHG_PROXIMITY_SNA" ;
VAL_ 541 CP_pilot 7 "CHG_PILOT_SNA" 6 "CHG_PILOT_UNUSED_6" 5 "CHG_PILOT_INVALID" 4 "CHG_PILOT_IDLE" 3 "CHG_PILOT_FAST_CHARGE" 2 "CHG_PILOT_LINE_CHARGE" 1 "CHG_PILOT_FAULTED" 0 "CHG_PILOT_NONE" ;
VAL_ 541 CP_cableType 5 "CHG_CABLE_TYPE_SNA" 4 "CHG_CABLE_TYPE_MCS" 3 "CHG_CABLE_TYPE_GB_DC" 2 "CHG_CABLE_TYPE_GB_AC" 1 "CHG_CABLE_TYPE_SAE" 0 "CHG_CABLE_TYPE_IEC" ;
VAL_ 541 CP_iecPilotState 9 "IEC_PILOT_SNA" 8 "IEC_PILOT_NUM" 7 "IEC_PILOT_F" 6 "IEC_PILOT_E" 5 "IEC_PILOT_C3" 4 "IEC_PILOT_C2" 3 "IEC_PILOT_C1" 2 "IEC_PILOT_B3" 1 "IEC_PILOT_B2" 0 "IEC_PILOT_B1" ;
VAL_ 541 CP_teslaSwcanState 8 "TESLA_SWCAN_V2L_ESTABLISHED" 7 "TESLA_SWCAN_V2L_RECEIVE" 6 "TESLA_SWCAN_OFFBOARD_UPDATE_IN_PROGRESS" 5 "TESLA_SWCAN_GO_TO_SLEEP" 4 "TESLA_SWCAN_FAULT" 3 "TESLA_SWCAN_ESTABLISHED" 2 "TESLA_SWCAN_RECEIVE" 1 "TESLA_SWCAN_ACCEPT" 0 "TESLA_SWCAN_INACTIVE" ;
VAL_ 541 CP_evseChargeType_UI 2 "AC_CHARGER_PRESENT" 1 "DC_CHARGER_PRESENT" 0 "NO_CHARGER_PRESENT" ;
VAL_ 541 CP_gbState 15 "GBDC_TESTER_PRESENT" 14 "GBDC_FAULTED" 13 "GBDC_RETRY_CHARGE" 12 "GBDC_ERROR_HANDLING" 11 "GBDC_END_OF_CHARGE" 10 "GBDC_CHARGE_DISABLING" 9 "GBDC_STOP_CHARGE_REQUESTED" 8 "GBDC_CHARGING" 7 "GBDC_READY_TO_CHARGE" 6 "GBDC_VEH_PACK_PRECHARGE" 5 "GBDC_CHARGE_PARAM_CONFIG" 4 "GBDC_RECOGNITION" 3 "GBDC_HANDSHAKING_EXT_ISO" 2 "GBDC_COMMS_RECEIVED" 1 "GBDC_WAIT_FOR_COMMS" 0 "GBDC_INACTIVE" ;
VAL_ 541 CP_gbdcStopChargeReason 8 "GBDC_PARAM_MISMATCH" 7 "GBDC_SUPERCHARGER_COMMS_TIMEOUT" 6 "GBDC_LIVE_DISCONNECT" 5 "GBDC_EVSE_CRITICAL_FAULT" 4 "GBDC_EVSE_FAULT" 3 "GBDC_COMMS_TIMEOUT" 2 "GBDC_EVSE_REQUESTED" 1 "GBDC_VEH_REQUESTED" 0 "GBDC_STOP_REASON_NONE" ;
VAL_ 541 CP_gbdcFailureReason 3 "GBDC_CRITICAL_FAILURE" 2 "GBDC_SHUTDOWN_FAILURE" 1 "GBDC_ATTEMPTS_EXPIRED" 0 "GBDC_FAILURE_NONE" ;
VAL_ 541 CP_acChargeState 6 "AC_CHARGE_FAULT" 5 "AC_CHARGE_VEH_SHUTDOWN" 4 "AC_CHARGE_ONBOARD_CHARGER_SHUTDOWN" 3 "AC_CHARGE_ENABLED" 2 "AC_CHARGE_STANDBY" 1 "AC_CHARGE_CONNECTED_CHARGE_BLOCKED" 0 "AC_CHARGE_INACTIVE" ;
VAL_ 541 CP_teslaDcState 10 "TESLA_DC_FAULT" 9 "TESLA_DC_EMERGENCY_SHUTDOWN" 8 "TESLA_DC_VEH_SHUTDOWN" 7 "TESLA_DC_EVSE_SHUTDOWN" 6 "TESLA_DC_ENABLED" 5 "TESLA_DC_EXT_PRECHARGE_ACTIVE" 4 "TESLA_DC_EXT_TEST_ACTIVE" 3 "TESLA_DC_EXT_TESTS_ENABLED" 2 "TESLA_DC_STANDBY" 1 "TESLA_DC_CONNECTED_CHARGE_BLOCKED" 0 "TESLA_DC_INACTIVE" ;
VAL_ 1001 DAS_headlightRequest 3 "DAS_HEADLIGHT_REQUEST_INVALID" 2 "DAS_HEADLIGHT_REQUEST_TAIL_LIGHTS_ONLY" 1 "DAS_HEADLIGHT_REQUEST_ON" 0 "DAS_HEADLIGHT_REQUEST_OFF" ;
VAL_ 1001 DAS_hazardLightRequest 3 "DAS_REQUEST_HAZARDS_SNA" 2 "DAS_REQUEST_HAZARDS_ON_FAST" 1 "DAS_REQUEST_HAZARDS_ON" 0 "DAS_REQUEST_HAZARDS_OFF" ;
VAL_ 1001 DAS_wiperSpeed 15 "DAS_WIPER_SPEED_INVALID" 14 "DAS_WIPER_SPEED_14" 13 "DAS_WIPER_SPEED_13" 12 "DAS_WIPER_SPEED_12" 11 "DAS_WIPER_SPEED_11" 10 "DAS_WIPER_SPEED_10" 9 "DAS_WIPER_SPEED_9" 8 "DAS_WIPER_SPEED_8" 7 "DAS_WIPER_SPEED_7" 6 "DAS_WIPER_SPEED_6" 5 "DAS_WIPER_SPEED_5" 4 "DAS_WIPER_SPEED_4" 3 "DAS_WIPER_SPEED_3" 2 "DAS_WIPER_SPEED_2" 1 "DAS_WIPER_SPEED_1" 0 "DAS_WIPER_SPEED_OFF" ;
VAL_ 1001 DAS_turnIndicatorRequest 4 "DAS_TURN_INDICATOR_DEFER" 3 "DAS_TURN_INDICATOR_CANCEL" 2 "DAS_TURN_INDICATOR_RIGHT" 1 "DAS_TURN_INDICATOR_LEFT" 0 "DAS_TURN_INDICATOR_NONE" ;
VAL_ 1001 DAS_highLowBeamDecision 3 "DAS_HIGH_BEAM_SNA" 2 "DAS_HIGH_BEAM_ON" 1 "DAS_HIGH_BEAM_OFF" 0 "DAS_HIGH_BEAM_UNDECIDED" ;
VAL_ 1001 DAS_heaterRequest 2 "DAS_HEATER_ON" 1 "DAS_HEATER_OFF" 0 "DAS_HEATER_SNA" ;
VAL_ 1001 DAS_highLowBeamOffReason 5 "HIGH_BEAM_OFF_REASON_SNA" 4 "HIGH_BEAM_OFF_REASON_HEAD_LIGHT" 3 "HIGH_BEAM_OFF_REASON_AMBIENT_LIGHT" 2 "HIGH_BEAM_OFF_REASON_MOVING_RADAR_TARGET" 1 "HIGH_BEAM_OFF_REASON_MOVING_VISION_TARGET" 0 "HIGH_BEAM_ON" ;
VAL_ 1001 DAS_mirrorFoldRequest 3 "DAS_MIRROR_REQUEST_SNA" 2 "DAS_MIRROR_REQUEST_UNFOLD" 1 "DAS_MIRROR_REQUEST_FOLD" 0 "DAS_MIRROR_REQUEST_NONE" ;
VAL_ 1001 DAS_autoWiperState 5 "DAS_AUTO_WIPER_STATE_SNA" 4 "DAS_AUTO_WIPER_STATE_FAST_CONTINUOUS" 3 "DAS_AUTO_WIPER_STATE_SLOW_CONTINUOUS" 2 "DAS_AUTO_WIPER_STATE_FAST_INTERMITTENT" 1 "DAS_AUTO_WIPER_STATE_SLOW_INTERMITTENT" 0 "DAS_AUTO_WIPER_STATE_OFF" ;
VAL_ 1001 DAS_turnIndicatorRequestReason 24 "DAS_ACTIVE_SIMULTANEOUS_LANE_CHANGE_AVOIDANCE" 23 "DAS_ACTIVE_INFEASIBLE_KINEMATICS_LANE_CHANGE" 22 "DAS_ACTIVE_STAY_OUT_OF_RIGHTMOST_LANE_LANE_CHANGE" 21 "DAS_ACTIVE_AWAY_FROM_MERGE_LANE_CHANGE" 20 "DAS_ACTIVE_EXIT_RIGHT_LANE_LANE_CHANGE" 19 "DAS_ACTIVE_EXIT_PASSING_LANE_LANE_CHANGE" 18 "DAS_ACTIVE_INCORRECT_ROAD_SIDE_LANE_CHANGE" 17 "DAS_ACTIVE_STATIC_OBJECT_LANE_CHANGE" 15 "DAS_CANCEL_MANUAL_BLINKER" 14 "DAS_CANCEL_AUTO_PARK" 13 "DAS_ACTIVE_AUTO_PARK" 12 "DAS_CANCEL_SUMMMON" 11 "DAS_ACTIVE_SUMMMON" 10 "DAS_CANCEL_INTERSECTION" 9 "DAS_ACTIVE_INTERSECTION" 8 "DAS_ACTIVE_COMMANDED_LANE_CHANGE" 7 "DAS_CANCEL_MERGE" 6 "DAS_ACTIVE_MERGE" 5 "DAS_CANCEL_FORK" 4 "DAS_CANCEL_LANE_CHANGE" 3 "DAS_ACTIVE_FORK" 2 "DAS_ACTIVE_SPEED_LANE_CHANGE" 1 "DAS_ACTIVE_NAV_LANE_CHANGE" 0 "DAS_NONE" ;
VAL_ 1001 DAS_restrictDoorReleaseLeft 1 "RESTRICT_DOOR_RELEASE_ACTIVE" 0 "RESTRICT_DOOR_RELEASE_INACTIVE" ;
VAL_ 1001 DAS_restrictDoorReleaseRight 1 "RESTRICT_DOOR_RELEASE_ACTIVE" 0 "RESTRICT_DOOR_RELEASE_INACTIVE" ;
VAL_ 634 DIF_hvilStatus 3 "SNA" 2 "CLOSED" 1 "OPEN" 0 "DISABLED" ;
VAL_ 634 DIF_hvilSupplyState 2 "ACTIVE" 1 "INACTIVE" 0 "NOT_AVAILABLE" ;
VAL_ 634 DIF_vBatQF 1 "QUALIFIED" 0 "NOT_QUALIFIED" ;
VAL_ 634 DIF_powerStageSafeState 3 "PSTG_SAFESTATE_3PS_LOW" 2 "PSTG_SAFESTATE_3PS_HIGH" 1 "PSTG_SAFESTATE_ALL_OFF" 0 "PSTG_SAFESTATE_NONE" ;
VAL_ 634 DIF_fluxState 12 "DI_FLUXSTATE_DISABLED" 11 "DI_FLUXSTATE_MAGNET_FLUX_DETECT" 10 "DI_FLUXSTATE_STATIONARY_WASTE" 9 "DI_FLUXSTATE_FAULT" 7 "DI_FLUXSTATE_VCONTROL" 6 "DI_FLUXSTATE_ICONTROL" 5 "DI_FLUXSTATE_ENABLED" 4 "DI_FLUXSTATE_FLUX_DOWN" 3 "DI_FLUXSTATE_FLUX_UP" 2 "DI_FLUXSTATE_STANDBY" 1 "DI_FLUXSTATE_TEST" 0 "DI_FLUXSTATE_START" ;
VAL_ 634 DIF_gateDriveState 4 "PSTG_GD_STATE_NOT_CONFIGURED" 3 "PSTG_GD_STATE_CONFIGURED" 2 "PSTG_GD_STATE_CONFIGURING" 1 "PSTG_GD_STATE_SELFTEST" 0 "PSTG_GD_STATE_INIT" ;
VAL_ 784 HVP_infoIndex 255 "END" 31 "SUBCOMPONENT_GITHASH" 30 "PACKAGE_SN_8_14" 29 "PACKAGE_SN_1_7" 27 "PACKAGE_PN_15_20" 26 "PACKAGE_PN_8_14" 25 "PACKAGE_PN_1_7" 23 "SUBCOMPONENT2" 22 "VARIANTCRC" 20 "UDS_PROTOCOL_BOOTCRC" 19 "VERSION_DEPRECATED" 18 "BOOTLOADER_GITHASH" 17 "APP_GITHASH" 16 "SUBCOMPONENT" 15 "BOOTLOADER_CRC" 14 "BOOTLOADER_SVN" 13 "APP_CRC" 11 "PCBAID_ASSYID_USAGEID" 10 "BUILD_HWID_COMPONENTID" 9 "DEPRECATED_9" 8 "DEPRECATED_8" 7 "DEPRECATED_7" 6 "DEPRECATED_6" 5 "DEPRECATED_5" 4 "DEPRECATED_4" 3 "DEPRECATED_3" 2 "DEPRECATED_2" 1 "DEPRECATED_1" 0 "DEPRECATED_0" ;
VAL_ 784 HVP_buildType 4 "INFO_MFG_BUILD" 3 "INFO_TRACEABLE_CI_BUILD" 2 "INFO_LOCAL_BUILD" 1 "INFO_PLATFORM_BUILD" 0 "INFO_UNKNOWN_BUILD" ;
VAL_ 941 ICR_infoIndex 255 "END" 31 "SUBCOMPONENT_GITHASH" 30 "PACKAGE_SN_8_14" 29 "PACKAGE_SN_1_7" 27 "PACKAGE_PN_15_20" 26 "PACKAGE_PN_8_14" 25 "PACKAGE_PN_1_7" 23 "SUBCOMPONENT2" 22 "VARIANTCRC" 20 "UDS_PROTOCOL_BOOTCRC" 19 "VERSION_DEPRECATED" 18 "BOOTLOADER_GITHASH" 17 "APP_GITHASH" 16 "SUBCOMPONENT" 15 "BOOTLOADER_CRC" 14 "BOOTLOADER_SVN" 13 "APP_CRC" 11 "PCBAID_ASSYID_USAGEID" 10 "BUILD_HWID_COMPONENTID" 9 "DEPRECATED_9" 8 "DEPRECATED_8" 7 "DEPRECATED_7" 6 "DEPRECATED_6" 5 "DEPRECATED_5" 4 "DEPRECATED_4" 3 "DEPRECATED_3" 2 "DEPRECATED_2" 1 "DEPRECATED_1" 0 "DEPRECATED_0" ;
VAL_ 941 ICR_infoBuildType 4 "INFO_MFG_BUILD" 3 "INFO_TRACEABLE_CI_BUILD" 2 "INFO_LOCAL_BUILD" 1 "INFO_PLATFORM_BUILD" 0 "INFO_UNKNOWN_BUILD" ;
VAL_ 964 PCS_infoIndex 255 "END" 31 "SUBCOMPONENT_GITHASH" 30 "PACKAGE_SN_8_14" 29 "PACKAGE_SN_1_7" 27 "PACKAGE_PN_15_20" 26 "PACKAGE_PN_8_14" 25 "PACKAGE_PN_1_7" 23 "SUBCOMPONENT2" 22 "VARIANTCRC" 20 "UDS_PROTOCOL_BOOTCRC" 19 "VERSION_DEPRECATED" 18 "BOOTLOADER_GITHASH" 17 "APP_GITHASH" 16 "SUBCOMPONENT" 15 "BOOTLOADER_CRC" 14 "BOOTLOADER_SVN" 13 "APP_CRC" 11 "PCBAID_ASSYID_USAGEID" 10 "BUILD_HWID_COMPONENTID" 9 "DEPRECATED_9" 8 "DEPRECATED_8" 7 "DEPRECATED_7" 6 "DEPRECATED_6" 5 "DEPRECATED_5" 4 "DEPRECATED_4" 3 "DEPRECATED_3" 2 "DEPRECATED_2" 1 "DEPRECATED_1" 0 "DEPRECATED_0" ;
VAL_ 964 PCS_buildType 4 "INFO_MFG_BUILD" 3 "INFO_TRACEABLE_CI_BUILD" 2 "INFO_LOCAL_BUILD" 1 "INFO_PLATFORM_BUILD" 0 "INFO_UNKNOWN_BUILD" ;
VAL_ 816 SCCM_infoIndex 255 "END" 20 "UDS_PROTOCOL_BOOTCRC" 18 "BOOTLOADER_SVNHASH" 17 "APP_SVNHASH" 16 "SUBCOMPONENT1" 14 "BOOTLOADER_SVN" 13 "APP_CRC" 11 "PCBAID_ASSYID_USAGEID" 10 "BUILD_HWID_COMPONENTID" ;
VAL_ 816 SCCM_infoBuildType 4 "INFO_MFG_BUILD" 3 "INFO_TRACEABLE_CI_BUILD" 2 "INFO_LOCAL_BUILD" 1 "INFO_PLATFORM_BUILD" 0 "INFO_UNKNOWN_BUILD" ;
VAL_ 1657 UI_rgbEnableState 2 "AUTO" 1 "ON" 0 "OFF" ;
VAL_ 1657 UI_rgbEffectType 20 "RAMP_5000MS" 19 "RAMP_4750MS" 18 "RAMP_4500MS" 17 "RAMP_4250MS" 16 "RAMP_4000MS" 15 "RAMP_3750MS" 14 "RAMP_3500MS" 13 "RAMP_3250MS" 12 "RAMP_3000MS" 11 "RAMP_2750MS" 10 "RAMP_2500MS" 9 "RAMP_2250MS" 8 "RAMP_2000MS" 7 "RAMP_1750MS" 6 "RAMP_1500MS" 5 "RAMP_1250MS" 4 "RAMP_1000MS" 3 "RAMP_750MS" 2 "RAMP_500MS" 1 "RAMP_250MS" 0 "RAMP_INSTANT" ;
VAL_ 1657 UI_rgbBrightnessLevel 127 "SNA" ;
VAL_ 819 UI_acChargeCurrentLimit 127 "SNA" ;
VAL_ 819 UI_chargePortLatchRequest 2 "UI_LATCH_REQUEST_DISENGAGE" 1 "UI_LATCH_REQUEST_ENGAGE" 0 "UI_LATCH_REQUEST_NONE" ;
VAL_ 819 UI_cpInletHeaterRequest 2 "HEATER_MANUAL_OVERRIDE" 1 "HEATER_AUTO" 0 "HEATER_OFF" ;
VAL_ 991 UI_userActivity 1 "USER_ACTIVE" 0 "USER_IDLE" ;
VAL_ 991 UI_linkState 2 "LINK_STATE_WIFI" 1 "LINK_STATE_CELL" 0 "LINK_STATE_NONE" ;
VAL_ 991 UI_mobileAppConnected 1 "CONNECTED" 0 "NOT_CONNECTED" ;
VAL_ 991 UI_autoshiftDRState 6 "AUTOSHIFT_DR_STATE_BRAKE_GEAR_SHIFT_CONFIRMED_D" 5 "AUTOSHIFT_DR_STATE_BRAKE_GEAR_SHIFT_CONFIRMED_R" 4 "AUTOSHIFT_DR_STATE_BRAKE_STEERING_AND_BRAKE_CONFIRMED" 3 "AUTOSHIFT_DR_STATE_ONLY_STEERING_CONFIRMED" 2 "AUTOSHIFT_DR_STATE_ONLY_BRAKE_CONFIRMED" 1 "AUTOSHIFT_DR_STATE_PROMPT_SHOWING_UNCONFIRMED" 0 "AUTOSHIFT_DR_STATE_INACTIVE" ;
VAL_ 991 UI_wifiBtModuleType 4 "ELEKTRA" 3 "TCU4G" 2 "BCM4359" 1 "QCA6595" 0 "UNKNOWN" ;
VAL_ 991 UI_selfParkState 255 "SNA" 52 "SELF_PARK_USER_PAUSED" 51 "SELF_PARK_REMOTE_PRE_ABORT" 50 "SELF_PARK_RESUME" 49 "SELF_PARK_PAUSE" 48 "SELF_PARK_DV_MISMATCH" 47 "SELF_PARK_DI_PANIC" 46 "SELF_PARK_POST_ACTIVE_FAILURE" 45 "SELF_PARK_POST_ACTIVE_SUCCESS" 44 "SELF_PARK_CANCEL_AUTO_SUMMON" 43 "SELF_PARK_REMOTE_ABORT" 42 "SELF_PARK_OBSTACLE_NOT_CLEARED" 41 "SELF_PARK_OBSTACLE_CLEARED" 40 "SELF_PARK_OPEN_GATE" 39 "SELF_PARK_ACTIVE" 38 "SELF_PARK_STARTED_REVERSE" 37 "SELF_PARK_STARTED_FORWARD" 36 "SELF_PARK_NOT_STARTED_TIMEOUT" 35 "SELF_PARK_PRIMED" 34 "SELF_PARK_PREPRIMED" 33 "SELF_PARK_TURN_ON_DRIVE_RAIL" 32 "SELF_PARK_DETECT_KEY_FOB" 31 "SELF_PARK_WAKE_UP_BUSES" 30 "SELF_PARK_CONNECTING_BLUETOOTH" 29 "SELF_PARK_UNAVAILABLE_CAR_WASH_MODE" 28 "SELF_PARK_UNAVAILABLE_CAR_ALARM" 27 "SELF_PARK_UNAVAILABLE_CRASH_STATE" 26 "SELF_PARK_UNAVAILABLE_DRAG_STRIP_MODE" 25 "SELF_PARK_UNAVAILABLE_TRACK_MODE" 24 "SELF_PARK_UNAVAILABLE_SERVICE_MODE" 23 "SELF_PARK_UNAVAILABLE_DOG_MODE" 22 "SELF_PARK_UNAVAILABLE_GAME_MODE" 21 "SELF_PARK_UNAVAILABLE_BLUETOOTH_CONNECT_TIMEOUT" 20 "SELF_PARK_UNAVAILABLE_WAKEUP_TIMEOUT" 19 "SELF_PARK_UNAVAILABLE_NO_BLUETOOTH_DEVICES_PAIRED" 18 "SELF_PARK_UNAVAILABLE_BRAKE_PRESSED" 17 "SELF_PARK_UNAVAILABLE_ROAD_GRADE" 16 "SELF_PARK_UNAVAILABLE_TRAILER_MODE" 15 "SELF_PARK_UNAVAILABLE_KEY_FOB_BATTERY_LOW" 14 "SELF_PARK_UNAVAILABLE_KEY_FOB_NOT_DETECTED" 13 "SELF_PARK_UNAVAILABLE_PARK_SENSOR_ISSUE" 12 "SELF_PARK_UNAVAILABLE_AUTOSTEER_NOT_ENABLED" 11 "SELF_PARK_UNAVAILABLE_LV_BUS_SUPPORT_ISSUE" 10 "SELF_PARK_UNAVAILABLE_ON_PUBLIC_ROAD" 9 "SELF_PARK_UNAVAILABLE_PARKED_TOO_LONG" 8 "SELF_PARK_UNAVAILABLE_DOOR_OPEN" 7 "SELF_PARK_UNAVAILABLE_TRUNK_OPEN" 6 "SELF_PARK_UNAVAILABLE_FRUNK_OPEN" 5 "SELF_PARK_UNAVAILABLE_PLUGGED_IN" 4 "SELF_PARK_UNAVAILABLE_NOT_PARKED" 3 "SELF_PARK_UNAVAILABLE" 2 "SELF_PARK_IDLE" 1 "SELF_PARK_DRIVING" 0 "SELF_PARK_DISABLED" ;
VAL_ 991 UI_summonDeviceIndex 3 "UNKNOWN" 2 "DEVICE_2" 1 "DEVICE_1" 0 "DEVICE_0" ;
VAL_ 663 UI_adaptiveRideRequest 3 "ADAPTIVE_RIDE_REQUEST_ADVANCED" 2 "ADAPTIVE_RIDE_REQUEST_SPORT" 1 "ADAPTIVE_RIDE_REQUEST_AUTO" 0 "ADAPTIVE_RIDE_REQUEST_COMFORT" ;
VAL_ 663 UI_geofenceLevelingRequest 5 "GEOFENCE_LEVELING_REQUEST_SNA" 4 "GEOFENCE_LEVELING_REQUEST_VERY_HIGH_PERSIST" 3 "GEOFENCE_LEVELING_REQUEST_HIGH_PERSIST" 2 "GEOFENCE_LEVELING_REQUEST_VERY_HIGH_TEMPORARY" 1 "GEOFENCE_LEVELING_REQUEST_HIGH_TEMPORARY" 0 "GEOFENCE_LEVELING_REQUEST_NONE" ;
VAL_ 947 UI_lightSwitch 4 "LIGHT_SWITCH_SNA" 3 "LIGHT_SWITCH_OFF" 2 "LIGHT_SWITCH_PARKING" 1 "LIGHT_SWITCH_ON" 0 "LIGHT_SWITCH_AUTO" ;
VAL_ 947 UI_autopilotPowerStateRequest 2 "AUTOPILOT_SUSPEND" 1 "AUTOPILOT_SENTRY" 0 "AUTOPILOT_NOMINAL" ;
VAL_ 947 UI_frontLeftSeatFanReq 3 "FAN_REQUEST_LEVEL3" 2 "FAN_REQUEST_LEVEL2" 1 "FAN_REQUEST_LEVEL1" 0 "FAN_REQUEST_OFF" ;
VAL_ 947 UI_frontRightSeatFanReq 3 "FAN_REQUEST_LEVEL3" 2 "FAN_REQUEST_LEVEL2" 1 "FAN_REQUEST_LEVEL1" 0 "FAN_REQUEST_OFF" ;
VAL_ 609 VCFRONT_12VBatteryStatusIndex 5 "Mux5" 4 "Mux4" 3 "Mux3" 2 "Mux2" 1 "Mux1" 0 "Mux0" ;
VAL_ 609 VCFRONT_batterySMState 10 "BATTERY_SM_STATE_EXTERNAL_LV_BUS_CONTROL" 9 "BATTERY_SM_STATE_RECOVERY" 8 "BATTERY_SM_STATE_FAULT" 7 "BATTERY_SM_STATE_SHORTED_CELL_TEST" 6 "BATTERY_SM_STATE_DISCONNECTED_BATTERY_TEST" 5 "BATTERY_SM_STATE_OTA_STANDBY" 4 "BATTERY_SM_STATE_RESISTANCE_ESTIMATION" 3 "BATTERY_SM_STATE_STANDBY" 2 "BATTERY_SM_STATE_DISCHARGE" 1 "BATTERY_SM_STATE_CHARGE" 0 "BATTERY_SM_STATE_INIT" ;
VAL_ 609 VCFRONT_eFuseRecoveryStateDBG 4 "VC_LVBMB_EFUSE_RECOVERY_STATE_BLOCKED" 3 "VC_LVBMB_EFUSE_RECOVERY_STATE_FINISH" 2 "VC_LVBMB_EFUSE_RECOVERY_STATE_CONNECT" 1 "VC_LVBMB_EFUSE_RECOVERY_STATE_SETUP" 0 "VC_LVBMB_EFUSE_RECOVERY_STATE_INACTIVE" ;
VAL_ 609 VCFRONT_batteryLINScheduleDBG 7 "VC_LVBMS_LIN_SCHEDULE_SNA" 6 "VC_LVBMS_LIN_SCHEDULE_OTHER" 4 "VC_LVBMS_LIN_SCHEDULE_DEFAULT_2" 3 "VC_LVBMS_LIN_SCHEDULE_DEFAULT_1" 2 "VC_LVBMS_LIN_SCHEDULE_DIAGNOSTIC" 1 "VC_LVBMS_LIN_SCHEDULE_RESET" 0 "VC_LVBMS_LIN_SCHEDULE_OFF" ;
VAL_ 609 VCFRONT_IBSVoltage 4095 "SNA" ;
VAL_ 609 VCFRONT_IBSTemperature 2047 "IBS_TEMPERATURE_SNA" ;
VAL_ 609 VCFRONT_LVBatteryStatusForDrive 2 "LV_BATTERY_EXIT_DRIVE_REQUESTED" 1 "LV_BATTERY_READY_FOR_DRIVE" 0 "LV_BATTERY_NOT_READY_FOR_DRIVE" ;
VAL_ 609 VCFRONT_LVBatteryType 5 "LV_BATTERY_TYPE_TESLA_48V_LI_ION" 4 "LV_BATTERY_TYPE_TESLA_16V_LI_ION" 3 "LV_BATTERY_TYPE_CATL_LI_ION" 2 "LV_BATTERY_TYPE_CLARIOS_B24_FLOODED" 1 "LV_BATTERY_TYPE_ATLASBX_B24_FLOODED" 0 "LV_BATTERY_TYPE_UNKNOWN" ;
VAL_ 609 VCFRONT_IBSVoltageFiltered 16383 "SNA" 16382 "MAX" 16381 "MIN" ;
VAL_ 609 VCFRONT_LVBMS_LVBusVoltageSource 3 "VC_LVBMS_VOLTAGE_SOURCE_LVBMS" 2 "VC_LVBMS_VOLTAGE_SOURCE_VBAT_MONITOR" 1 "VC_LVBMS_VOLTAGE_SOURCE_IBS" 0 "VC_LVBMS_VOLTAGE_SOURCE_NONE" ;
VAL_ 609 VCFRONT_LVBMS_LVPackCurrentSourc 2 "VC_LV_PACK_CURRENT_SOURCE_LVBMS" 1 "VC_LV_PACK_CURRENT_SOURCE_IBS" 0 "VC_LV_PACK_CURRENT_SOURCE_NONE" ;
VAL_ 609 VCFRONT_LVBatterySupportRqrdTrig 14336 "LV_BATTERY_SUPPORT_REQUIRED_TRIGGER_SOC_IMBALANCE_AND_CORRECTION" 12288 "LV_BATTERY_SUPPORT_REQUIRED_TRIGGER_IMBALANCE_AND_CORRECTION" 10240 "LV_BATTERY_SUPPORT_REQUIRED_TRIGGER_SOC_AND_CORRECTION" 8192 "LV_BATTERY_SUPPORT_REQUIRED_TRIGGER_CORRECTION" 6144 "LV_BATTERY_SUPPORT_REQUIRED_TRIGGER_SOC_AND_IMBALANCE" 4096 "LV_BATTERY_SUPPORT_REQUIRED_TRIGGER_IMBALANCE" 2048 "LV_BATTERY_SUPPORT_REQUIRED_TRIGGER_SOC" 1024 "LV_BATTERY_SUPPORT_REQUIRED_TRIGGER_POST_OTA" 512 "LV_BATTERY_SUPPORT_REQUIRED_TRIGGER_EXIT_TRANSPORT_MODE" 256 "LV_BATTERY_SUPPORT_REQUIRED_TRIGGER_POWER_ON_RESET" 128 "LV_BATTERY_SUPPORT_REQUIRED_TRIGGER_PERIODIC_CHARGE" 64 "LV_BATTERY_SUPPORT_REQUIRED_TRIGGER_AH_COUNT" 32 "LV_BATTERY_SUPPORT_REQUIRED_TRIGGER_UNKNOWN_VOLTAGE" 20 "LV_BATTERY_SUPPORT_REQUIRED_TRIGGER_RAW_VC_VOLTAGES" 16 "LV_BATTERY_SUPPORT_REQUIRED_TRIGGER_VBAT_RAW_VOLTAGE" 12 "LV_BATTERY_SUPPORT_REQUIRED_TRIGGER_RAW_BATTERY_VOLTAGES" 10 "LV_BATTERY_SUPPORT_REQUIRED_TRIGGER_PACK_VOLTAGES" 8 "LV_BATTERY_SUPPORT_REQUIRED_TRIGGER_PACK_RAW_VOLTAGE" 5 "LV_BATTERY_SUPPORT_REQUIRED_TRIGGER_IBS_VOLTAGES" 4 "LV_BATTERY_SUPPORT_REQUIRED_TRIGGER_IBS_RAW_VOLTAGE" 3 "LV_BATTERY_SUPPORT_REQUIRED_TRIGGER_FILTERED_VOLTAGES" 2 "LV_BATTERY_SUPPORT_REQUIRED_TRIGGER_PACK_FILTERED_VOLTAGE" 1 "LV_BATTERY_SUPPORT_REQUIRED_TRIGGER_IBS_FILTERED_VOLTAGE" 0 "LV_BATTERY_SUPPORT_REQUIRED_TRIGGER_NONE" ;
VAL_ 609 VCFRONT_voltageProfile 3 "VOLTAGE_PROFILE_ALWAYS_CLOSED_CONTACTORS" 2 "VOLTAGE_PROFILE_REDUCED_FLOAT" 1 "VOLTAGE_PROFILE_FLOAT" 0 "VOLTAGE_PROFILE_CHARGE" ;
VAL_ 609 VCFRONT_IBSVoltageRawDBG 16383 "SNA" 16382 "MAX" 16381 "MIN" ;
VAL_ 1801 VCFRONT_logging0point1HzIndex 31 "END" 30 "HEADLAMP_LEFT_ECULESS_IO_DIAGNOSTIC" 29 "HEADLAMP_RIGHT_ECULESS_IO_DIAGNOSTIC" 28 "COMPRESSOR_WEAR_COUNTERS" 27 "HEADLAMP_RIGHT_EEPROM_INFO" 26 "HEADLAMP_LEFT_EEPROM_INFO" 25 "EXV_VALVE_TYPES" 24 "PART_FAILURE_CONFIDENCE_CONTINUED" 23 "PART_FAILURE_CONFIDENCE" 22 "LIGHT_DEBUG" 21 "HEADLAMP_COMM_FAULT_COUNTERS" 20 "HEADLAMP_MIGRATION" 19 "EXV_TOTAL_DISTANCE_COUNTERS_3" 18 "EXV_TOTAL_DISTANCE_COUNTERS_2" 17 "EXV_TOTAL_DISTANCE_COUNTERS_1" 16 "EXV_CCR_COUNTERS_2" 15 "EXV_CCR_COUNTERS_1" 14 "EXV_CCL_COUNTERS_2" 13 "EXV_CCL_COUNTERS_1" 12 "EXV_LCC_COUNTERS_2" 11 "EXV_LCC_COUNTERS_1" 10 "EXV_RECIRC_COUNTERS_2" 9 "EXV_RECIRC_COUNTERS_1" 8 "EXV_EVAPORATOR_COUNTERS_2" 7 "EXV_EVAPORATOR_COUNTERS_1" 6 "EXV_CHILLER_COUNTERS_2" 5 "EXV_CHILLER_COUNTERS_1" 4 "HEADLAMP_AIMED_POSITION" 3 "HEADLAMP_CURRENT_POSITION" 2 "HCMR_LED_TEMPS" 1 "HCML_LED_TEMPS" 0 "LIGHT_CURRENTS" ;
VAL_ 1801 VC_hcmlFactoryOfOrigin 3 "HELLA_MEXICO" 2 "HELLA_SLOVAKIA" 1 "HELLA_CHINA" 0 "UNKNOWN" ;
VAL_ 1801 VC_hcmlHellaPartNumberStatus 1 "FAULT" 0 "OK" ;
VAL_ 1801 VC_hcmlCurrentBinMappingType 2 "BIN_MAP_TYPE_2" 1 "BIN_MAP_TYPE_1" 0 "BIN_MAP_TYPE_UNKNOWN" ;
VAL_ 1801 VC_hcmlCurrentBin0Value 7 "INVALID_LIGHTCLASS" 4 "LIGHTCLASS_4" 3 "LIGHTCLASS_3" 2 "LIGHTCLASS_2" 1 "LIGHTCLASS_1" 0 "LIGHTCLASS_SNA" ;
VAL_ 1801 VC_hcmlCurrentBin1Value 7 "INVALID_LIGHTCLASS" 4 "LIGHTCLASS_4" 3 "LIGHTCLASS_3" 2 "LIGHTCLASS_2" 1 "LIGHTCLASS_1" 0 "LIGHTCLASS_SNA" ;
VAL_ 1801 VC_hcmlCurrentBin2Value 7 "INVALID_LIGHTCLASS" 4 "LIGHTCLASS_4" 3 "LIGHTCLASS_3" 2 "LIGHTCLASS_2" 1 "LIGHTCLASS_1" 0 "LIGHTCLASS_SNA" ;
VAL_ 1801 VC_hcmlCurrentBin3Value 7 "INVALID_LIGHTCLASS" 4 "LIGHTCLASS_4" 3 "LIGHTCLASS_3" 2 "LIGHTCLASS_2" 1 "LIGHTCLASS_1" 0 "LIGHTCLASS_SNA" ;
VAL_ 1801 VC_hcmlCurrentBin4Value 7 "INVALID_LIGHTCLASS" 4 "LIGHTCLASS_4" 3 "LIGHTCLASS_3" 2 "LIGHTCLASS_2" 1 "LIGHTCLASS_1" 0 "LIGHTCLASS_SNA" ;
VAL_ 1801 VC_hcmlCurrentBin5Value 7 "INVALID_LIGHTCLASS" 4 "LIGHTCLASS_4" 3 "LIGHTCLASS_3" 2 "LIGHTCLASS_2" 1 "LIGHTCLASS_1" 0 "LIGHTCLASS_SNA" ;
VAL_ 1801 VC_hcmlRegionAndSide 6 "HEADLAMP_REGION_AND_SIDE_ECE_RHD_RIGHT" 5 "HEADLAMP_REGION_AND_SIDE_ECE_RHD_LEFT" 4 "HEADLAMP_REGION_AND_SIDE_ECE_LHD_RIGHT" 3 "HEADLAMP_REGION_AND_SIDE_ECE_LHD_LEFT" 2 "HEADLAMP_REGION_AND_SIDE_SAE_RIGHT" 1 "HEADLAMP_REGION_AND_SIDE_SAE_LEFT" 0 "HEADLAMP_REGION_AND_SIDE_SNA" ;
VAL_ 1801 VC_hcmrFactoryOfOrigin 3 "HELLA_MEXICO" 2 "HELLA_SLOVAKIA" 1 "HELLA_CHINA" 0 "UNKNOWN" ;
VAL_ 1801 VC_hcmrHellaPartNumberStatus 1 "FAULT" 0 "OK" ;
VAL_ 1801 VC_hcmrCurrentBinMappingType 2 "BIN_MAP_TYPE_2" 1 "BIN_MAP_TYPE_1" 0 "BIN_MAP_TYPE_UNKNOWN" ;
VAL_ 1801 VC_hcmrCurrentBin0Value 7 "INVALID_LIGHTCLASS" 4 "LIGHTCLASS_4" 3 "LIGHTCLASS_3" 2 "LIGHTCLASS_2" 1 "LIGHTCLASS_1" 0 "LIGHTCLASS_SNA" ;
VAL_ 1801 VC_hcmrCurrentBin1Value 7 "INVALID_LIGHTCLASS" 4 "LIGHTCLASS_4" 3 "LIGHTCLASS_3" 2 "LIGHTCLASS_2" 1 "LIGHTCLASS_1" 0 "LIGHTCLASS_SNA" ;
VAL_ 1801 VC_hcmrCurrentBin2Value 7 "INVALID_LIGHTCLASS" 4 "LIGHTCLASS_4" 3 "LIGHTCLASS_3" 2 "LIGHTCLASS_2" 1 "LIGHTCLASS_1" 0 "LIGHTCLASS_SNA" ;
VAL_ 1801 VC_hcmrCurrentBin3Value 7 "INVALID_LIGHTCLASS" 4 "LIGHTCLASS_4" 3 "LIGHTCLASS_3" 2 "LIGHTCLASS_2" 1 "LIGHTCLASS_1" 0 "LIGHTCLASS_SNA" ;
VAL_ 1801 VC_hcmrCurrentBin4Value 7 "INVALID_LIGHTCLASS" 4 "LIGHTCLASS_4" 3 "LIGHTCLASS_3" 2 "LIGHTCLASS_2" 1 "LIGHTCLASS_1" 0 "LIGHTCLASS_SNA" ;
VAL_ 1801 VC_hcmrCurrentBin5Value 7 "INVALID_LIGHTCLASS" 4 "LIGHTCLASS_4" 3 "LIGHTCLASS_3" 2 "LIGHTCLASS_2" 1 "LIGHTCLASS_1" 0 "LIGHTCLASS_SNA" ;
VAL_ 1801 VC_hcmrRegionAndSide 6 "HEADLAMP_REGION_AND_SIDE_ECE_RHD_RIGHT" 5 "HEADLAMP_REGION_AND_SIDE_ECE_RHD_LEFT" 4 "HEADLAMP_REGION_AND_SIDE_ECE_LHD_RIGHT" 3 "HEADLAMP_REGION_AND_SIDE_ECE_LHD_LEFT" 2 "HEADLAMP_REGION_AND_SIDE_SAE_RIGHT" 1 "HEADLAMP_REGION_AND_SIDE_SAE_LEFT" 0 "HEADLAMP_REGION_AND_SIDE_SNA" ;
VAL_ 897 VCFRONT_logging1HzIndex 26 "END" 25 "MISC_FOUR" 24 "POWER_RATIONALITY_VCRIGHT" 23 "POWER_RATIONALITY_VCLEFT" 22 "SLEEP_WAKE" 21 "MISC_THREE" 20 "HSD_CURRENTS_2" 19 "HSD_CURRENTS_1" 18 "MISC_TWO" 17 "HP_PT_TARGETS" 16 "COOLANT_2" 15 "BODY_CONTROL" 14 "HP_MODE_OPTIONS_AND_ESTIMATES" 13 "HP_MODE_SELECT_AND_ESTIMATES" 12 "HP_ARBITRATION" 11 "HP_PRESSURE_CONTROL" 10 "HP_TEMPS_AND_DEMANDS" 9 "HP_DISSIPATION_AND_POWER" 8 "HP_EXV_CALIBRATION" 7 "HP_CYCLE_MODEL" 6 "HP_CONTROL_LOOP_AND_STATE" 5 "HP_DATA_AND_ACCUMULATORS" 4 "HP_EXV_RANGE" 3 "MISC_ONE" 2 "COOLANT_VALVE" 1 "FAN_DEMAND_CONDENSER_AND_FET_TEMPS" 0 "COOLANT" ;
VAL_ 897 VCFRONT_batteryDischArbState 5 "FAULTED" 4 "INHIBIT_FOR_REST" 3 "BATTERY_DISCHARGE" 2 "BATTERY_HEATING" 1 "READY" 0 "NOT_READY" ;
VAL_ 957 VCFRONT_energyLossIndex 4 "SINCE_LAST_CHARGE2" 3 "SINCE_LAST_CHARGE" 2 "SINCE_LAST_DRIVE2" 1 "SINCE_LAST_DRIVE" 0 "STATUS" ;
